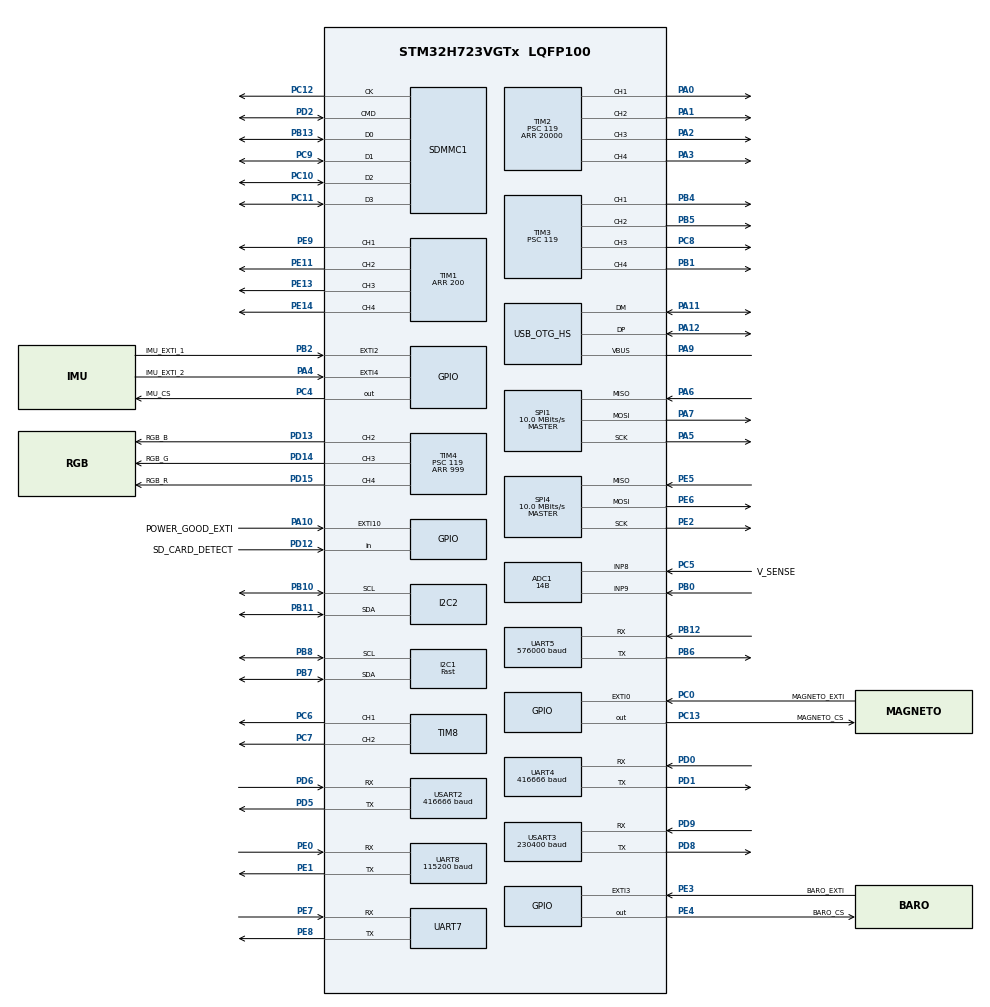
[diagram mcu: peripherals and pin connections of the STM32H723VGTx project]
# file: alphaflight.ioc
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ADC1.Channel-0\#ChannelRegularConversion=ADC_CHANNEL_8
ADC1.Channel-1\#ChannelRegularConversion=ADC_CHANNEL_9
ADC1.ClockPrescaler=ADC_CLOCK_ASYNC_DIV8
ADC1.ConversionDataManagement=ADC_CONVERSIONDATA_DMA_ONESHOT
ADC1.NbrOfConversion=2
ADC1.NbrOfConversionFlag=1
ADC1.OffsetNumber-0\#ChannelRegularConversion=ADC_OFFSET_NONE
ADC1.OffsetNumber-1\#ChannelRegularConversion=ADC_OFFSET_NONE
ADC1.OffsetSignedSaturation-0\#ChannelRegularConversion=DISABLE
ADC1.OversamplingMode=ENABLE
ADC1.Rank-0\#ChannelRegularConversion=1
ADC1.Rank-1\#ChannelRegularConversion=2
ADC1.Ratio=32
ADC1.Resolution=ADC_RESOLUTION_14B
ADC1.RightBitShift=ADC_RIGHTBITSHIFT_5
ADC1.SamplingTime-0\#ChannelRegularConversion=ADC_SAMPLETIME_64CYCLES_5
ADC1.SamplingTime-1\#ChannelRegularConversion=ADC_SAMPLETIME_64CYCLES_5
ADC1.master=1
CORTEX_M7.AccessPermission_Spec=MPU_REGION_FULL_ACCESS
CORTEX_M7.BaseAddress_Spec=0x24000000
CORTEX_M7.CPU_DCache=Enabled
CORTEX_M7.CPU_ICache=Enabled
CORTEX_M7.Enable_S-Cortex_Memory_Protection_Unit_Region1_Settings_S=__NULL
CORTEX_M7.Enable_Spec=MPU_REGION_ENABLE
CORTEX_M7.IsShareable_Spec=MPU_ACCESS_NOT_SHAREABLE
CORTEX_M7.MPU_Control=MPU_HFNMI_PRIVDEF
CORTEX_M7.Size_Spec=MPU_REGION_SIZE_32KB
CORTEX_M7.SubRegionDisable_Spec=0x00
CORTEX_M7.TypeExtField_Spec=MPU_TEX_LEVEL1
CORTEX_M7.default_mode_Activation=1
CRC.InputDataFormat=CRC_INPUTDATA_FORMAT_WORDS
CRC.InputDataInversionMode=CRC_INPUTDATA_INVERSION_BYTE
CRC.OutputDataInversionMode=CRC_OUTPUTDATA_INVERSION_ENABLE
Dma.ADC1.9.Direction=DMA_PERIPH_TO_MEMORY
Dma.ADC1.9.EventEnable=DISABLE
Dma.ADC1.9.FIFOMode=DMA_FIFOMODE_DISABLE
Dma.ADC1.9.Instance=DMA1_Stream4
Dma.ADC1.9.MemDataAlignment=DMA_MDATAALIGN_WORD
Dma.ADC1.9.MemInc=DMA_MINC_ENABLE
Dma.ADC1.9.Mode=DMA_NORMAL
Dma.ADC1.9.PeriphDataAlignment=DMA_PDATAALIGN_WORD
Dma.ADC1.9.PeriphInc=DMA_PINC_DISABLE
Dma.ADC1.9.Polarity=HAL_DMAMUX_REQ_GEN_RISING
Dma.ADC1.9.Priority=DMA_PRIORITY_LOW
Dma.ADC1.9.RequestNumber=1
Dma.ADC1.9.SignalID=NONE
Dma.ADC1.9.SyncEnable=DISABLE
Dma.ADC1.9.SyncPolarity=HAL_DMAMUX_SYNC_NO_EVENT
Dma.ADC1.9.SyncRequestNumber=1
Dma.ADC1.9.SyncSignalID=NONE
Dma.Request0=TIM8_UP
Dma.Request1=SPI1_RX
Dma.Request2=SPI1_TX
Dma.Request3=TIM1_UP
Dma.Request4=USART2_RX
Dma.Request5=USART3_RX
Dma.Request6=UART8_RX
Dma.Request7=UART8_TX
Dma.Request8=USART2_TX
Dma.Request9=ADC1
Dma.SPI1_RX.1.Direction=DMA_PERIPH_TO_MEMORY
Dma.SPI1_RX.1.EventEnable=DISABLE
Dma.SPI1_RX.1.FIFOMode=DMA_FIFOMODE_DISABLE
Dma.SPI1_RX.1.Instance=DMA2_Stream0
Dma.SPI1_RX.1.MemDataAlignment=DMA_MDATAALIGN_BYTE
Dma.SPI1_RX.1.MemInc=DMA_MINC_ENABLE
Dma.SPI1_RX.1.Mode=DMA_NORMAL
Dma.SPI1_RX.1.PeriphDataAlignment=DMA_PDATAALIGN_BYTE
Dma.SPI1_RX.1.PeriphInc=DMA_PINC_DISABLE
Dma.SPI1_RX.1.Polarity=HAL_DMAMUX_REQ_GEN_RISING
Dma.SPI1_RX.1.Priority=DMA_PRIORITY_VERY_HIGH
Dma.SPI1_RX.1.RequestNumber=1
Dma.SPI1_RX.1.SignalID=NONE
Dma.SPI1_RX.1.SyncEnable=DISABLE
Dma.SPI1_RX.1.SyncPolarity=HAL_DMAMUX_SYNC_NO_EVENT
Dma.SPI1_RX.1.SyncRequestNumber=1
Dma.SPI1_RX.1.SyncSignalID=NONE
Dma.SPI1_TX.2.Direction=DMA_MEMORY_TO_PERIPH
Dma.SPI1_TX.2.EventEnable=DISABLE
Dma.SPI1_TX.2.FIFOMode=DMA_FIFOMODE_DISABLE
Dma.SPI1_TX.2.Instance=DMA2_Stream1
Dma.SPI1_TX.2.MemDataAlignment=DMA_MDATAALIGN_BYTE
Dma.SPI1_TX.2.MemInc=DMA_MINC_ENABLE
Dma.SPI1_TX.2.Mode=DMA_NORMAL
Dma.SPI1_TX.2.PeriphDataAlignment=DMA_PDATAALIGN_BYTE
Dma.SPI1_TX.2.PeriphInc=DMA_PINC_DISABLE
Dma.SPI1_TX.2.Polarity=HAL_DMAMUX_REQ_GEN_RISING
Dma.SPI1_TX.2.Priority=DMA_PRIORITY_VERY_HIGH
Dma.SPI1_TX.2.RequestNumber=1
Dma.SPI1_TX.2.SignalID=NONE
Dma.SPI1_TX.2.SyncEnable=DISABLE
Dma.SPI1_TX.2.SyncPolarity=HAL_DMAMUX_SYNC_NO_EVENT
Dma.SPI1_TX.2.SyncRequestNumber=1
Dma.SPI1_TX.2.SyncSignalID=NONE
Dma.TIM1_UP.3.Direction=DMA_MEMORY_TO_PERIPH
Dma.TIM1_UP.3.EventEnable=DISABLE
Dma.TIM1_UP.3.FIFOMode=DMA_FIFOMODE_DISABLE
Dma.TIM1_UP.3.Instance=DMA1_Stream0
Dma.TIM1_UP.3.MemDataAlignment=DMA_MDATAALIGN_HALFWORD
Dma.TIM1_UP.3.MemInc=DMA_MINC_ENABLE
Dma.TIM1_UP.3.Mode=DMA_NORMAL
Dma.TIM1_UP.3.PeriphDataAlignment=DMA_PDATAALIGN_HALFWORD
Dma.TIM1_UP.3.PeriphInc=DMA_PINC_DISABLE
Dma.TIM1_UP.3.Polarity=HAL_DMAMUX_REQ_GEN_RISING
Dma.TIM1_UP.3.Priority=DMA_PRIORITY_VERY_HIGH
Dma.TIM1_UP.3.RequestNumber=1
Dma.TIM1_UP.3.SignalID=NONE
Dma.TIM1_UP.3.SyncEnable=DISABLE
Dma.TIM1_UP.3.SyncPolarity=HAL_DMAMUX_SYNC_NO_EVENT
Dma.TIM1_UP.3.SyncRequestNumber=1
Dma.TIM1_UP.3.SyncSignalID=NONE
Dma.TIM8_UP.0.Direction=DMA_PERIPH_TO_MEMORY
Dma.TIM8_UP.0.EventEnable=DISABLE
Dma.TIM8_UP.0.FIFOMode=DMA_FIFOMODE_DISABLE
Dma.TIM8_UP.0.Instance=DMA1_Stream1
Dma.TIM8_UP.0.MemDataAlignment=DMA_MDATAALIGN_HALFWORD
Dma.TIM8_UP.0.MemInc=DMA_MINC_ENABLE
Dma.TIM8_UP.0.Mode=DMA_NORMAL
Dma.TIM8_UP.0.PeriphDataAlignment=DMA_PDATAALIGN_HALFWORD
Dma.TIM8_UP.0.PeriphInc=DMA_PINC_DISABLE
Dma.TIM8_UP.0.Polarity=HAL_DMAMUX_REQ_GEN_RISING
Dma.TIM8_UP.0.Priority=DMA_PRIORITY_HIGH
Dma.TIM8_UP.0.RequestNumber=1
Dma.TIM8_UP.0.SignalID=NONE
Dma.TIM8_UP.0.SyncEnable=DISABLE
Dma.TIM8_UP.0.SyncPolarity=HAL_DMAMUX_SYNC_NO_EVENT
Dma.TIM8_UP.0.SyncRequestNumber=1
Dma.TIM8_UP.0.SyncSignalID=NONE
Dma.UART8_RX.6.Direction=DMA_PERIPH_TO_MEMORY
Dma.UART8_RX.6.EventEnable=DISABLE
Dma.UART8_RX.6.FIFOMode=DMA_FIFOMODE_DISABLE
Dma.UART8_RX.6.Instance=DMA1_Stream5
Dma.UART8_RX.6.MemDataAlignment=DMA_MDATAALIGN_BYTE
Dma.UART8_RX.6.MemInc=DMA_MINC_ENABLE
Dma.UART8_RX.6.Mode=DMA_CIRCULAR
Dma.UART8_RX.6.PeriphDataAlignment=DMA_PDATAALIGN_BYTE
Dma.UART8_RX.6.PeriphInc=DMA_PINC_DISABLE
Dma.UART8_RX.6.Polarity=HAL_DMAMUX_REQ_GEN_RISING
Dma.UART8_RX.6.Priority=DMA_PRIORITY_LOW
Dma.UART8_RX.6.RequestNumber=1
Dma.UART8_RX.6.SignalID=NONE
Dma.UART8_RX.6.SyncEnable=DISABLE
Dma.UART8_RX.6.SyncPolarity=HAL_DMAMUX_SYNC_NO_EVENT
Dma.UART8_RX.6.SyncRequestNumber=1
Dma.UART8_RX.6.SyncSignalID=NONE
Dma.UART8_TX.7.Direction=DMA_MEMORY_TO_PERIPH
Dma.UART8_TX.7.EventEnable=DISABLE
Dma.UART8_TX.7.FIFOMode=DMA_FIFOMODE_DISABLE
Dma.UART8_TX.7.Instance=DMA1_Stream6
Dma.UART8_TX.7.MemDataAlignment=DMA_MDATAALIGN_BYTE
Dma.UART8_TX.7.MemInc=DMA_MINC_ENABLE
Dma.UART8_TX.7.Mode=DMA_NORMAL
Dma.UART8_TX.7.PeriphDataAlignment=DMA_PDATAALIGN_BYTE
Dma.UART8_TX.7.PeriphInc=DMA_PINC_DISABLE
Dma.UART8_TX.7.Polarity=HAL_DMAMUX_REQ_GEN_RISING
Dma.UART8_TX.7.Priority=DMA_PRIORITY_LOW
Dma.UART8_TX.7.RequestNumber=1
Dma.UART8_TX.7.SignalID=NONE
Dma.UART8_TX.7.SyncEnable=DISABLE
Dma.UART8_TX.7.SyncPolarity=HAL_DMAMUX_SYNC_NO_EVENT
Dma.UART8_TX.7.SyncRequestNumber=1
Dma.UART8_TX.7.SyncSignalID=NONE
Dma.USART2_RX.4.Direction=DMA_PERIPH_TO_MEMORY
Dma.USART2_RX.4.EventEnable=DISABLE
Dma.USART2_RX.4.FIFOMode=DMA_FIFOMODE_DISABLE
Dma.USART2_RX.4.Instance=DMA1_Stream2
Dma.USART2_RX.4.MemDataAlignment=DMA_MDATAALIGN_BYTE
Dma.USART2_RX.4.MemInc=DMA_MINC_ENABLE
Dma.USART2_RX.4.Mode=DMA_CIRCULAR
Dma.USART2_RX.4.PeriphDataAlignment=DMA_PDATAALIGN_BYTE
Dma.USART2_RX.4.PeriphInc=DMA_PINC_DISABLE
Dma.USART2_RX.4.Polarity=HAL_DMAMUX_REQ_GEN_RISING
Dma.USART2_RX.4.Priority=DMA_PRIORITY_HIGH
Dma.USART2_RX.4.RequestNumber=1
Dma.USART2_RX.4.SignalID=NONE
Dma.USART2_RX.4.SyncEnable=DISABLE
Dma.USART2_RX.4.SyncPolarity=HAL_DMAMUX_SYNC_NO_EVENT
Dma.USART2_RX.4.SyncRequestNumber=1
Dma.USART2_RX.4.SyncSignalID=NONE
Dma.USART2_TX.8.Direction=DMA_MEMORY_TO_PERIPH
Dma.USART2_TX.8.EventEnable=DISABLE
Dma.USART2_TX.8.FIFOMode=DMA_FIFOMODE_DISABLE
Dma.USART2_TX.8.Instance=DMA1_Stream7
Dma.USART2_TX.8.MemDataAlignment=DMA_MDATAALIGN_BYTE
Dma.USART2_TX.8.MemInc=DMA_MINC_ENABLE
Dma.USART2_TX.8.Mode=DMA_NORMAL
Dma.USART2_TX.8.PeriphDataAlignment=DMA_PDATAALIGN_BYTE
Dma.USART2_TX.8.PeriphInc=DMA_PINC_DISABLE
Dma.USART2_TX.8.Polarity=HAL_DMAMUX_REQ_GEN_RISING
Dma.USART2_TX.8.Priority=DMA_PRIORITY_LOW
Dma.USART2_TX.8.RequestNumber=1
Dma.USART2_TX.8.SignalID=NONE
Dma.USART2_TX.8.SyncEnable=DISABLE
Dma.USART2_TX.8.SyncPolarity=HAL_DMAMUX_SYNC_NO_EVENT
Dma.USART2_TX.8.SyncRequestNumber=1
Dma.USART2_TX.8.SyncSignalID=NONE
Dma.USART3_RX.5.Direction=DMA_PERIPH_TO_MEMORY
Dma.USART3_RX.5.EventEnable=DISABLE
Dma.USART3_RX.5.FIFOMode=DMA_FIFOMODE_DISABLE
Dma.USART3_RX.5.Instance=DMA1_Stream3
Dma.USART3_RX.5.MemDataAlignment=DMA_MDATAALIGN_BYTE
Dma.USART3_RX.5.MemInc=DMA_MINC_ENABLE
Dma.USART3_RX.5.Mode=DMA_CIRCULAR
Dma.USART3_RX.5.PeriphDataAlignment=DMA_PDATAALIGN_BYTE
Dma.USART3_RX.5.PeriphInc=DMA_PINC_DISABLE
Dma.USART3_RX.5.Polarity=HAL_DMAMUX_REQ_GEN_RISING
Dma.USART3_RX.5.Priority=DMA_PRIORITY_MEDIUM
Dma.USART3_RX.5.RequestNumber=1
Dma.USART3_RX.5.SignalID=NONE
Dma.USART3_RX.5.SyncEnable=DISABLE
Dma.USART3_RX.5.SyncPolarity=HAL_DMAMUX_SYNC_NO_EVENT
Dma.USART3_RX.5.SyncRequestNumber=1
Dma.USART3_RX.5.SyncSignalID=NONE
I2C1.I2C_Speed_Mode=I2C_Fast
I2C1.Timing=0x00501E6C
I2C2.Timing=0x107075B0
Mcu.Family=STM32H7
Mcu.Name=STM32H723VGTx
Mcu.Package=LQFP100
NVIC.DMA1_Stream0_IRQn=true\:0\:0\:false\:false\:true\:false\:true\:true
NVIC.DMA1_Stream1_IRQn=true\:0\:0\:false\:false\:true\:false\:true\:true
NVIC.DMA1_Stream2_IRQn=true\:0\:0\:false\:false\:true\:false\:true\:true
NVIC.DMA1_Stream3_IRQn=true\:0\:0\:false\:false\:true\:false\:true\:true
NVIC.DMA1_Stream4_IRQn=true\:0\:0\:false\:false\:true\:false\:true\:true
NVIC.DMA1_Stream5_IRQn=true\:0\:0\:false\:false\:true\:false\:true\:true
NVIC.DMA1_Stream6_IRQn=true\:0\:0\:false\:false\:true\:false\:true\:true
NVIC.DMA1_Stream7_IRQn=true\:0\:0\:false\:false\:true\:false\:true\:true
NVIC.DMA2_Stream0_IRQn=true\:0\:0\:false\:false\:true\:false\:true\:true
NVIC.DMA2_Stream1_IRQn=true\:0\:0\:false\:false\:true\:false\:true\:true
NVIC.EXTI0_IRQn=true\:13\:0\:true\:false\:true\:true\:true\:true
NVIC.EXTI2_IRQn=true\:5\:0\:true\:false\:true\:true\:true\:true
NVIC.EXTI3_IRQn=true\:14\:0\:true\:false\:true\:true\:true\:true
NVIC.EXTI4_IRQn=true\:6\:0\:true\:false\:true\:true\:true\:true
NVIC.OTG_HS_IRQn=true\:0\:0\:false\:false\:true\:false\:true\:true
NVIC.PriorityGroup=NVIC_PRIORITYGROUP_4
NVIC.SDMMC1_IRQn=true\:0\:0\:false\:false\:true\:true\:true\:true
NVIC.SPI1_IRQn=true\:0\:0\:false\:false\:true\:false\:true\:true
NVIC.UART4_IRQn=true\:0\:0\:false\:false\:true\:true\:true\:true
NVIC.UART5_IRQn=true\:0\:0\:false\:false\:true\:true\:true\:true
NVIC.UART8_IRQn=true\:0\:0\:false\:false\:true\:true\:true\:true
NVIC.USART2_IRQn=true\:0\:0\:false\:false\:true\:true\:true\:true
NVIC.USART3_IRQn=true\:0\:0\:false\:false\:true\:true\:true\:true
PA0.GPIO_Speed=GPIO_SPEED_FREQ_HIGH
PA0.Signal=S_TIM2_CH1_ETR
PA1.GPIO_Speed=GPIO_SPEED_FREQ_HIGH
PA1.Signal=S_TIM2_CH2
PA10.GPIO_Label=POWER_GOOD_EXTI
PA10.Signal=GPXTI10
PA11.Mode=Device_Only_FS
PA11.Signal=USB_OTG_HS_DM
PA12.Mode=Device_Only_FS
PA12.Signal=USB_OTG_HS_DP
PA13(JTMS/SWDIO).Mode=Trace_Asynchronous_SW
PA13(JTMS/SWDIO).Signal=DEBUG_JTMS-SWDIO
PA14(JTCK/SWCLK).Mode=Trace_Asynchronous_SW
PA14(JTCK/SWCLK).Signal=DEBUG_JTCK-SWCLK
PA2.GPIO_Speed=GPIO_SPEED_FREQ_HIGH
PA2.Signal=S_TIM2_CH3
PA3.GPIO_Speed=GPIO_SPEED_FREQ_HIGH
PA3.Signal=S_TIM2_CH4
PA4.GPIO_Label=IMU_EXTI_2
PA4.Signal=GPXTI4
PA5.Mode=Full_Duplex_Master
PA5.Signal=SPI1_SCK
PA6.Mode=Full_Duplex_Master
PA6.Signal=SPI1_MISO
PA7.Mode=Full_Duplex_Master
PA7.Signal=SPI1_MOSI
PA9.Mode=Activate_VBUS_FS
PA9.Signal=USB_OTG_HS_VBUS
PB0.Signal=ADCx_INP9
PB1.GPIO_Speed=GPIO_SPEED_FREQ_HIGH
PB1.Signal=S_TIM3_CH4
PB10.Mode=I2C
PB10.Signal=I2C2_SCL
PB11.Mode=I2C
PB11.Signal=I2C2_SDA
PB12.Mode=Asynchronous
PB12.Signal=UART5_RX
PB13.Mode=SD_4_bits_Wide_bus
PB13.Signal=SDMMC1_D0
PB2.GPIO_Label=IMU_EXTI_1
PB2.GPIO_ModeDefaultEXTI=GPIO_MODE_IT_RISING
PB2.GPIO_PuPd=GPIO_NOPULL
PB2.Signal=GPXTI2
PB3(JTDO/TRACESWO).Mode=Trace_Asynchronous_SW
PB3(JTDO/TRACESWO).Signal=DEBUG_JTDO-SWO
PB4(NJTRST).GPIO_Speed=GPIO_SPEED_FREQ_HIGH
PB4(NJTRST).Signal=S_TIM3_CH1
PB5.GPIO_Speed=GPIO_SPEED_FREQ_HIGH
PB5.Signal=S_TIM3_CH2
PB6.Mode=Asynchronous
PB6.Signal=UART5_TX
PB7.Mode=I2C
PB7.Signal=I2C1_SDA
PB8.Mode=I2C
PB8.Signal=I2C1_SCL
PC0.GPIO_Label=MAGNETO_EXTI
PC0.Signal=GPXTI0
PC10.Mode=SD_4_bits_Wide_bus
PC10.Signal=SDMMC1_D2
PC11.Mode=SD_4_bits_Wide_bus
PC11.Signal=SDMMC1_D3
PC12.Mode=SD_4_bits_Wide_bus
PC12.Signal=SDMMC1_CK
PC13.GPIO_Label=MAGNETO_CS
PC13.Signal=GPIO_Output
PC4.GPIO_Label=IMU_CS
PC4.Signal=GPIO_Output
PC5.GPIO_Label=V_SENSE
PC5.Signal=ADCx_INP8
PC6.Signal=S_TIM8_CH1
PC7.Signal=S_TIM8_CH2
PC8.GPIO_Speed=GPIO_SPEED_FREQ_HIGH
PC8.Signal=S_TIM3_CH3
PC9.Mode=SD_4_bits_Wide_bus
PC9.Signal=SDMMC1_D1
PD0.Mode=Asynchronous
PD0.Signal=UART4_RX
PD1.Mode=Asynchronous
PD1.Signal=UART4_TX
PD12.GPIO_Label=SD_CARD_DETECT
PD12.Signal=GPIO_Input
PD13.GPIO_Label=RGB_B
PD13.Signal=S_TIM4_CH2
PD14.GPIO_Label=RGB_G
PD14.Signal=S_TIM4_CH3
PD15.GPIO_Label=RGB_R
PD15.Signal=S_TIM4_CH4
PD2.Mode=SD_4_bits_Wide_bus
PD2.Signal=SDMMC1_CMD
PD5.Mode=Asynchronous
PD5.Signal=USART2_TX
PD6.Mode=Asynchronous
PD6.Signal=USART2_RX
PD8.Mode=Asynchronous
PD8.Signal=USART3_TX
PD9.Mode=Asynchronous
PD9.Signal=USART3_RX
PE0.Mode=Asynchronous
PE0.Signal=UART8_RX
PE1.Mode=Asynchronous
PE1.Signal=UART8_TX
PE11.GPIO_Speed=GPIO_SPEED_FREQ_VERY_HIGH
PE11.Signal=S_TIM1_CH2
PE13.GPIO_Speed=GPIO_SPEED_FREQ_VERY_HIGH
PE13.Signal=S_TIM1_CH3
PE14.GPIO_Speed=GPIO_SPEED_FREQ_VERY_HIGH
PE14.Signal=S_TIM1_CH4
PE2.Mode=Full_Duplex_Master
PE2.Signal=SPI4_SCK
PE3.GPIO_Label=BARO_EXTI
PE3.Signal=GPXTI3
PE4.GPIO_Label=BARO_CS
PE4.Signal=GPIO_Output
PE5.Mode=Full_Duplex_Master
PE5.Signal=SPI4_MISO
PE6.Mode=Full_Duplex_Master
PE6.Signal=SPI4_MOSI
PE7.Mode=Asynchronous
PE7.Signal=UART7_RX
PE8.Mode=Asynchronous
PE8.Signal=UART7_TX
PE9.GPIO_Speed=GPIO_SPEED_FREQ_VERY_HIGH
PE9.Signal=S_TIM1_CH1
PH0-OSC_IN.Mode=HSE-External-Clock-Source
PH0-OSC_IN.Signal=RCC_OSC_IN
ProjectManager.HeapSize=0x200
ProjectManager.StackSize=0x400
ProjectManager.TargetToolchain=Makefile
RCC.ADCCLockSelection=RCC_ADCCLKSOURCE_PLL3
RCC.ADCFreq_Value=60000000
RCC.APB1Freq_Value=120000000
RCC.APB2Freq_Value=120000000
RCC.APB3Freq_Value=120000000
RCC.APB4Freq_Value=120000000
RCC.CKPERSourceSelection=RCC_CLKPSOURCE_HSE
RCC.CortexFreq_Value=480000000
RCC.DIVM1=8
RCC.DIVM2=8
RCC.DIVM3=8
RCC.DIVN1=120
RCC.DIVN2=120
RCC.DIVN3=120
RCC.DIVP1=1
RCC.DIVP2=24
RCC.DIVP3=1
RCC.DIVQ1=10
RCC.DIVQ2=24
RCC.DIVQ3=8
RCC.DIVR1=10
RCC.DIVR2=4
RCC.DIVR3=8
RCC.HCLKFreq_Value=120000000
RCC.HPRE=RCC_HCLK_DIV4
RCC.HSE_VALUE=32000000
RCC.I2C123CLockSelection=RCC_I2C1235CLKSOURCE_PLL3
RCC.LSE_VALUE=32.768
RCC.PLL1_VCI_Range-AdvancedSettings=RCC_PLL1VCIRANGE_0
RCC.PLL1_VCO_SEL-AdvancedSettings=RCC_PLL1VCOMEDIUM
RCC.PLL2FRACN=0
RCC.PLL2_VCI_Range-AdvancedSettings=RCC_PLL2VCIRANGE_0
RCC.PLL2_VCO_SEL-AdvancedSettings=RCC_PLL2VCOMEDIUM
RCC.PLL3FRACN=0
RCC.PLL3_VCI_Range-AdvancedSettings=RCC_PLL3VCIRANGE_2
RCC.PLL3_VCO_SEL-AdvancedSettings=RCC_PLL3VCOWIDE
RCC.PLLFRACN=0
RCC.PLLSourceVirtual=RCC_PLLSOURCE_HSE
RCC.SDMMC1CLockSelection=RCC_SDMMCCLKSOURCE_PLL2
RCC.SPI123CLockSelection=RCC_SPI123CLKSOURCE_PLL2
RCC.SYSCLKFreq_VALUE=480000000
RCC.SYSCLKSource=RCC_SYSCLKSOURCE_PLLCLK
RCC.Spi45ClockSelection=RCC_SPI45CLKSOURCE_PLL2
RCC.USART234578CLockSelection=RCC_USART234578CLKSOURCE_PLL3
RCC.USBFreq_Value=48000000
SDMMC1.ClockDiv=3
SDMMC1.HardwareFlowControl=SDMMC_HARDWARE_FLOW_CONTROL_ENABLE
SH.ADCx_INP8.0=ADC1_INP8,IN8-Single-Ended
SH.ADCx_INP9.0=ADC1_INP9,IN9-Single-Ended
SH.ADCx_INP9.1=ADC2_INP9
SH.S_TIM1_CH1.0=TIM1_CH1,PWM Generation1 CH1
SH.S_TIM1_CH2.0=TIM1_CH2,PWM Generation2 CH2
SH.S_TIM1_CH3.0=TIM1_CH3,PWM Generation3 CH3
SH.S_TIM1_CH4.0=TIM1_CH4,PWM Generation4 CH4
SH.S_TIM2_CH1_ETR.0=TIM2_CH1,PWM Generation1 CH1
SH.S_TIM2_CH2.0=TIM2_CH2,PWM Generation2 CH2
SH.S_TIM2_CH3.0=TIM2_CH3,PWM Generation3 CH3
SH.S_TIM2_CH4.0=TIM2_CH4,PWM Generation4 CH4
SH.S_TIM3_CH1.0=TIM3_CH1,PWM Generation1 CH1
SH.S_TIM3_CH2.0=TIM3_CH2,PWM Generation2 CH2
SH.S_TIM3_CH3.0=TIM3_CH3,PWM Generation3 CH3
SH.S_TIM3_CH4.0=TIM3_CH4,PWM Generation4 CH4
SH.S_TIM4_CH2.0=TIM4_CH2,PWM Generation2 CH2
SH.S_TIM4_CH3.0=TIM4_CH3,PWM Generation3 CH3
SH.S_TIM4_CH4.0=TIM4_CH4,PWM Generation4 CH4
SH.S_TIM8_CH1.0=TIM8_CH1,Output Compare1 CH1
SH.S_TIM8_CH2.0=TIM8_CH2,Output Compare2 CH2
SPI1.BaudRatePrescaler=SPI_BAUDRATEPRESCALER_2
SPI1.CalculateBaudRate=10.0 MBits/s
SPI1.DataSize=SPI_DATASIZE_8BIT
SPI1.Direction=SPI_DIRECTION_2LINES
SPI1.Mode=SPI_MODE_MASTER
SPI1.VirtualType=VM_MASTER
SPI4.BaudRatePrescaler=SPI_BAUDRATEPRESCALER_2
SPI4.CalculateBaudRate=10.0 MBits/s
SPI4.DataSize=SPI_DATASIZE_8BIT
SPI4.Direction=SPI_DIRECTION_2LINES
SPI4.Mode=SPI_MODE_MASTER
SPI4.VirtualType=VM_MASTER
TIM1.AutoReloadPreload=TIM_AUTORELOAD_PRELOAD_ENABLE
TIM1.Channel-PWM\ Generation1\ CH1=TIM_CHANNEL_1
TIM1.Channel-PWM\ Generation2\ CH2=TIM_CHANNEL_2
TIM1.Channel-PWM\ Generation3\ CH3=TIM_CHANNEL_3
TIM1.Channel-PWM\ Generation4\ CH4=TIM_CHANNEL_4
TIM1.OCFastMode_PWM-PWM\ Generation4\ CH4=TIM_OCFAST_DISABLE
TIM1.Period=200
TIM2.AutoReloadPreload=TIM_AUTORELOAD_PRELOAD_ENABLE
TIM2.Channel-PWM\ Generation1\ CH1=TIM_CHANNEL_1
TIM2.Channel-PWM\ Generation2\ CH2=TIM_CHANNEL_2
TIM2.Channel-PWM\ Generation3\ CH3=TIM_CHANNEL_3
TIM2.Channel-PWM\ Generation4\ CH4=TIM_CHANNEL_4
TIM2.Period=20000
TIM2.Prescaler=119
TIM23.ClockDivision=TIM_CLOCKDIVISION_DIV1
TIM23.Period=4294967295
TIM23.Prescaler=59999
TIM24.Prescaler=119
TIM3.Channel-PWM\ Generation1\ CH1=TIM_CHANNEL_1
TIM3.Channel-PWM\ Generation2\ CH2=TIM_CHANNEL_2
TIM3.Channel-PWM\ Generation3\ CH3=TIM_CHANNEL_3
TIM3.Channel-PWM\ Generation4\ CH4=TIM_CHANNEL_4
TIM3.Prescaler=119
TIM4.AutoReloadPreload=TIM_AUTORELOAD_PRELOAD_ENABLE
TIM4.Channel-PWM\ Generation2\ CH2=TIM_CHANNEL_2
TIM4.Channel-PWM\ Generation3\ CH3=TIM_CHANNEL_3
TIM4.Channel-PWM\ Generation4\ CH4=TIM_CHANNEL_4
TIM4.ClockDivision=TIM_CLOCKDIVISION_DIV1
TIM4.Period=999
TIM4.Prescaler=119
TIM8.Channel-Output\ Compare1\ CH1=TIM_CHANNEL_1
TIM8.Channel-Output\ Compare2\ CH2=TIM_CHANNEL_2
UART4.BaudRate=416666
UART5.BaudRate=576000
UART8.BaudRate=115200
UART8.StopBits=UART_STOPBITS_1
USART2.BaudRate=416666
USART2.VirtualMode-Asynchronous=VM_ASYNC
USART3.BaudRate=230400
USART3.VirtualMode-Asynchronous=VM_ASYNC
USB_DEVICE.CLASS_NAME_HS=CDC
USB_DEVICE.VirtualMode=Cdc
USB_DEVICE.VirtualModeHS=Cdc_HS
USB_OTG_HS.VirtualMode-Device_Only_FS=Device_Only_FS
VP_CORDIC_VS_CORDIC.Mode=CORDIC_Activate
VP_CRC_VS_CRC.Mode=CRC_Activate
VP_MEMORYMAP_VS_MEMORYMAP.Mode=CurAppReg
VP_TIM1_VS_ClockSourceINT.Mode=Internal
VP_TIM23_VS_ClockSourceINT.Mode=Internal
VP_TIM24_VS_ClockSourceINT.Mode=Internal
VP_TIM2_VS_ClockSourceINT.Mode=Internal
VP_TIM3_VS_ClockSourceINT.Mode=Internal
VP_TIM4_VS_ClockSourceINT.Mode=Internal
VP_USB_DEVICE_VS_USB_DEVICE_CDC_HS.Mode=CDC_HS
board=custom

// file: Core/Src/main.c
/* USER CODE BEGIN Header */
/**
  ******************************************************************************
  * @file           : main.c
  * @brief          : Main program body
  ******************************************************************************
  * @attention
  *
  * Copyright (c) 2026 STMicroelectronics.
  * All rights reserved.
  *
  * This software is licensed under terms that can be found in the LICENSE file
  * in the root directory of this software component.
  * If no LICENSE file comes with this software, it is provided AS-IS.
  *
  ******************************************************************************
  */
/* USER CODE END Header */
#include "main.h"
#include "usb_device.h"

/* USER CODE BEGIN Includes */
#include "common.h"
#include "sd.h"
#include "gps.h"
#include "lsm6dso.h"
#include "bmp390.h"
#include "timer.h"
#include "scheduler.h"
#include "spi.h"
#include "usbd_cdc.h"
#include "status_led.h"
#include "usb.h"
#include "config.h"
#include "dshot.h"
#include "serial_passthrough.h"
#include "crossfire.h"
#include "logger.h"
#include "flight_control.h"
#include "filesystem.h"
#include "osd.h"
#include "mmc5983ma.h"
#include "power_measurement.h"
/* USER CODE END Includes */

/* USER CODE BEGIN PM */

static inline uint32_t HZ_TO_US(float hz){
    if (hz <= 0.0f) return 0xFFFFFFFF; // avoid div by zero
    float period = 1.0f / hz * 1e6f;
    if (period > 0xFFFFFFFF) return 0xFFFFFFFF; // clamp to max uint32
    return (uint32_t)period;
}

/* USER CODE END PM */

ADC_HandleTypeDef hadc1;
DMA_HandleTypeDef hdma_adc1;

I2C_HandleTypeDef hi2c1;
I2C_HandleTypeDef hi2c2;

SD_HandleTypeDef hsd1;

SPI_HandleTypeDef hspi1;
SPI_HandleTypeDef hspi4;
DMA_HandleTypeDef hdma_spi1_rx;
DMA_HandleTypeDef hdma_spi1_tx;

UART_HandleTypeDef huart4;
UART_HandleTypeDef huart5;
UART_HandleTypeDef huart7;
UART_HandleTypeDef huart8;
UART_HandleTypeDef huart2;
UART_HandleTypeDef huart3;
DMA_HandleTypeDef hdma_uart8_rx;
DMA_HandleTypeDef hdma_uart8_tx;
DMA_HandleTypeDef hdma_usart2_rx;
DMA_HandleTypeDef hdma_usart2_tx;
DMA_HandleTypeDef hdma_usart3_rx;

void SystemClock_Config(void);
void PeriphCommonClock_Config(void);
static void MPU_Config(void);
static void MX_GPIO_Init(void);
static void MX_DMA_Init(void);
static void MX_CORDIC_Init(void);
static void MX_CRC_Init(void);
static void MX_SPI1_Init(void);
static void MX_TIM1_Init(void);
static void MX_TIM2_Init(void);
static void MX_TIM3_Init(void);
static void MX_TIM24_Init(void);
static void MX_I2C1_Init(void);
static void MX_SDMMC1_SD_Init(void);
static void MX_UART4_Init(void);
static void MX_UART5_Init(void);
static void MX_UART7_Init(void);
static void MX_UART8_Init(void);
static void MX_USART2_UART_Init(void);
static void MX_USART3_UART_Init(void);
static void MX_I2C2_Init(void);
static void MX_SPI4_Init(void);
static void MX_TIM8_Init(void);
static void MX_TIM4_Init(void);
static void MX_TIM23_Init(void);
static void MX_ADC1_Init(void);

int main(void)
{

  /* MPU Configuration--------------------------------------------------------*/
  MPU_Config();

  /* Enable the CPU Cache */

  /* Enable I-Cache---------------------------------------------------------*/
  SCB_EnableICache();

  /* Enable D-Cache---------------------------------------------------------*/
  SCB_EnableDCache();

  /* MCU Configuration--------------------------------------------------------*/

  /* Reset of all peripherals, Initializes the Flash interface and the Systick. */
  HAL_Init();

  /* Configure the system clock */
  SystemClock_Config();

  /* Configure the peripherals common clocks */
  PeriphCommonClock_Config();

  /* Initialize all configured peripherals */
  MX_GPIO_Init();
  MX_DMA_Init();
  MX_CORDIC_Init();
  MX_CRC_Init();
  MX_SPI1_Init();
  MX_TIM1_Init();
  MX_TIM2_Init();
  MX_TIM3_Init();
  MX_TIM24_Init();
  MX_I2C1_Init();
  MX_SDMMC1_SD_Init();
  MX_UART4_Init();
  MX_UART5_Init();
  MX_UART7_Init();
  MX_UART8_Init();
  MX_USART2_UART_Init();
  MX_USART3_UART_Init();
  MX_I2C2_Init();
  MX_SPI4_Init();
  MX_TIM8_Init();
  MX_USB_DEVICE_Init();
  MX_TIM4_Init();
  MX_TIM23_Init();
  MX_ADC1_Init();
  /* USER CODE BEGIN 2 */

  STATUS_LED_INIT();

  //PASSTHROUGH_START(&huart8);

  extern uint32_t alphaflight_cpp_test(void);

  uint32_t result = alphaflight_cpp_test();

  if(CONFIG_STORE_TO_SD_DEFAULTS() != CONFIG_OKAY) Error_Handler();

  if(CONFIG_LOAD_FROM_SD() != CONFIG_OKAY) Error_Handler();   // load complete FC config

  //fs_reset_superblock();

  if(TIMER_INIT(TIM23, TIM24) != TIMER_INIT_OKAY) Error_Handler();  // timer init for MICROS32 and MILLIS32

  if(TIMER_START() != TIMER_OKAY) Error_Handler();    // start MICROS32 and MILLIS32 timers

  SPI_INIT(SPI_DEVICE_IMU, &hspi1, GPIOC, LL_GPIO_PIN_4);   // initialize SPI devices
  SPI_INIT(SPI_DEVICE_BARO, &hspi4, GPIOE, LL_GPIO_PIN_4);
  SPI_INIT(SPI_DEVICE_MAGNETO, &hspi4, GPIOC, LL_GPIO_PIN_13);

  int32_t imu_task_index = SCHEDULER_REGISTER_TASK(IMU_READ_DATA, 600, false, 500, 800, 25, "Gyro Read");  // init IMU and register task in case of DRDY mode
  if(IMU_INIT(SPI_DEVICE_IMU, imu_task_index, &hdma_spi1_rx) != IMU_OKAY) Error_Handler();

  FS_LOAD_SUPERBLOCK();

  SERVO_INIT(TIM2, TIM3);

  if(BARO_INIT(SPI_DEVICE_BARO) != BARO_OKAY) Error_Handler();

  if(MAGNETO_INIT(SPI_DEVICE_MAGNETO) != MAGNETO_OKAY) Error_Handler();

  DSHOT_INIT();

  SCHEDULER_REGISTER_TASK(DSHOT_TRANSMIT, HZ_TO_US(1000), false, 0, 0, 20, "DSHOT TX");
  CRSF_SET_PARSER_TASK_PID(SCHEDULER_REGISTER_TASK(CRSF_PARSE_DMA, 100, false, 50, 150, 50, "CRSF Parsing"));
  GPS_SET_PARSER_TASK_PID(SCHEDULER_REGISTER_TASK(GPS_PARSE_DMA, 100, false, 50, 150, 50, "GPS Parsing"));
  SCHEDULER_REGISTER_TASK(FC_DIRECT_LAW, HZ_TO_US(200), false, 0, 0, 10, "FC Dir Law");
  LOG_SET_TASK_PID(SCHEDULER_REGISTER_TASK(LOG_RUN, HZ_TO_US(LOG_GET_FREQUENCY()), false, 0, 0, 10, "SD Logger"));
  SCHEDULER_REGISTER_TASK(BARO_READ_DATA, HZ_TO_US(25), false, HZ_TO_US(30), HZ_TO_US(20), 30, "Baro read");
  SCHEDULER_REGISTER_TASK(CRSF_TELEMETRY, HZ_TO_US(20), false, 0, 0, 10, "CRSF Telemetry");
  SCHEDULER_REGISTER_TASK(POWER_MEASUREMENT_START_DMA_READ, HZ_TO_US(100), false, 100, 100, 100, "ADC DMA start");
  //SCHEDULER_REGISTER_TASK(SCHEDULER_PRINT_TASK_PAGE, HZ_TO_US(10), false, 90000, 110000, 500, "USB Stats");
  //SCHEDULER_REGISTER_TASK(USB_STATUS, HZ_TO_US(60), false, 90000, 110000, 500, "USB Stats");

  GPS_INIT(&huart3);
  CRSF_INIT(&huart2);
  OSD_INIT(&huart8);
  POWER_MEASUREMENT_INIT(&hadc1);
  STATUS_LED_SET_ALL(20);

  /* USER CODE END 2 */

  /* Infinite loop */
  /* USER CODE BEGIN WHILE */
  while (1)
  {
    SCHEDULER_LOOP();

    /*if(latch == 0 && (MILLIS32() - now) > 20000){
      LOG_START();
      now = MILLIS32();
      latch = 1;
      STATUS_LED_SET_ALL(999);
    }

    if(latch == 1 && (MILLIS32() - now) > 20000){
      LOG_END();
      latch = 2;
      STATUS_LED_SET_ALL(20);
    }*/

    /* USER CODE END WHILE */

    /* USER CODE BEGIN 3 */
    /*
    Debug pin on S1:
    volatile static bool debug = false;

    GPIOA->MODER &= ~(uint32_t)0x03;
    GPIOA->MODER |= (uint32_t)0x01;

    if(debug){
        GPIOA->BSRR = 0x01;
    }
    else{
        GPIOA->BSRR = 0x01 << 16;
    }
    debug = !debug;
    */
  }
  /* USER CODE END 3 */
}

void SystemClock_Config(void)
{
  LL_FLASH_SetLatency(LL_FLASH_LATENCY_2);
  while(LL_FLASH_GetLatency()!= LL_FLASH_LATENCY_2)
  {
  }
  LL_PWR_ConfigSupply(LL_PWR_LDO_SUPPLY);
  LL_PWR_SetRegulVoltageScaling(LL_PWR_REGU_VOLTAGE_SCALE2);
  while (LL_PWR_IsActiveFlag_VOS() == 0)
  {
  }
  LL_RCC_HSE_EnableBypass();
  LL_RCC_HSE_Enable();

   /* Wait till HSE is ready */
  while(LL_RCC_HSE_IsReady() != 1)
  {

  }
  LL_RCC_PLL_SetSource(LL_RCC_PLLSOURCE_HSE);
  LL_RCC_PLL1P_Enable();
  LL_RCC_PLL1Q_Enable();
  LL_RCC_PLL1R_Enable();
  LL_RCC_PLL1_SetVCOInputRange(LL_RCC_PLLINPUTRANGE_4_8);
  LL_RCC_PLL1_SetVCOOutputRange(LL_RCC_PLLVCORANGE_WIDE);
  LL_RCC_PLL1_SetM(8);
  LL_RCC_PLL1_SetN(120);
  LL_RCC_PLL1_SetP(1);
  LL_RCC_PLL1_SetQ(10);
  LL_RCC_PLL1_SetR(10);
  LL_RCC_PLL1_Enable();

   /* Wait till PLL is ready */
  while(LL_RCC_PLL1_IsReady() != 1)
  {
  }

   /* Intermediate AHB prescaler 2 when target frequency clock is higher than 80 MHz */
   LL_RCC_SetAHBPrescaler(LL_RCC_AHB_DIV_2);

  LL_RCC_SetSysClkSource(LL_RCC_SYS_CLKSOURCE_PLL1);

   /* Wait till System clock is ready */
  while(LL_RCC_GetSysClkSource() != LL_RCC_SYS_CLKSOURCE_STATUS_PLL1)
  {

  }
  LL_RCC_SetSysPrescaler(LL_RCC_SYSCLK_DIV_1);
  LL_RCC_SetAHBPrescaler(LL_RCC_AHB_DIV_4);
  LL_RCC_SetAPB1Prescaler(LL_RCC_APB1_DIV_1);
  LL_RCC_SetAPB2Prescaler(LL_RCC_APB2_DIV_1);
  LL_RCC_SetAPB3Prescaler(LL_RCC_APB3_DIV_1);
  LL_RCC_SetAPB4Prescaler(LL_RCC_APB4_DIV_1);
  LL_SetSystemCoreClock(480000000);

   /* Update the time base */
  if (HAL_InitTick (TICK_INT_PRIORITY) != HAL_OK)
  {
    Error_Handler();
  }
}

void PeriphCommonClock_Config(void)
{
  LL_RCC_PLL2P_Enable();
  LL_RCC_PLL2Q_Enable();
  LL_RCC_PLL2R_Enable();
  LL_RCC_PLL2_SetVCOInputRange(LL_RCC_PLLINPUTRANGE_4_8);
  LL_RCC_PLL2_SetVCOOutputRange(LL_RCC_PLLVCORANGE_WIDE);
  LL_RCC_PLL2_SetM(8);
  LL_RCC_PLL2_SetN(120);
  LL_RCC_PLL2_SetP(24);
  LL_RCC_PLL2_SetQ(24);
  LL_RCC_PLL2_SetR(4);
  LL_RCC_PLL2_Enable();

   /* Wait till PLL is ready */
  while(LL_RCC_PLL2_IsReady() != 1)
  {
  }

  LL_RCC_PLL3Q_Enable();
  LL_RCC_PLL3R_Enable();
  LL_RCC_PLL3_SetVCOInputRange(LL_RCC_PLLINPUTRANGE_4_8);
  LL_RCC_PLL3_SetVCOOutputRange(LL_RCC_PLLVCORANGE_WIDE);
  LL_RCC_PLL3_SetM(8);
  LL_RCC_PLL3_SetN(120);
  LL_RCC_PLL3_SetP(1);
  LL_RCC_PLL3_SetQ(8);
  LL_RCC_PLL3_SetR(8);
  LL_RCC_PLL3_Enable();

   /* Wait till PLL is ready */
  while(LL_RCC_PLL3_IsReady() != 1)
  {
  }

}

static void MX_ADC1_Init(void)
{

  ADC_MultiModeTypeDef multimode = {0};
  ADC_ChannelConfTypeDef sConfig = {0};

  /** Common config
  */
  hadc1.Instance = ADC1;
  hadc1.Init.ClockPrescaler = ADC_CLOCK_ASYNC_DIV8;
  hadc1.Init.Resolution = ADC_RESOLUTION_14B;
  hadc1.Init.ScanConvMode = ADC_SCAN_ENABLE;
  hadc1.Init.EOCSelection = ADC_EOC_SINGLE_CONV;
  hadc1.Init.LowPowerAutoWait = DISABLE;
  hadc1.Init.ContinuousConvMode = DISABLE;
  hadc1.Init.NbrOfConversion = 2;
  hadc1.Init.DiscontinuousConvMode = DISABLE;
  hadc1.Init.ExternalTrigConv = ADC_SOFTWARE_START;
  hadc1.Init.ExternalTrigConvEdge = ADC_EXTERNALTRIGCONVEDGE_NONE;
  hadc1.Init.ConversionDataManagement = ADC_CONVERSIONDATA_DMA_ONESHOT;
  hadc1.Init.Overrun = ADC_OVR_DATA_PRESERVED;
  hadc1.Init.LeftBitShift = ADC_LEFTBITSHIFT_NONE;
  hadc1.Init.OversamplingMode = ENABLE;
  hadc1.Init.Oversampling.Ratio = 32;
  hadc1.Init.Oversampling.RightBitShift = ADC_RIGHTBITSHIFT_5;
  hadc1.Init.Oversampling.TriggeredMode = ADC_TRIGGEREDMODE_SINGLE_TRIGGER;
  hadc1.Init.Oversampling.OversamplingStopReset = ADC_REGOVERSAMPLING_CONTINUED_MODE;
  if (HAL_ADC_Init(&hadc1) != HAL_OK)
  {
    Error_Handler();
  }

  /** Configure the ADC multi-mode
  */
  multimode.Mode = ADC_MODE_INDEPENDENT;
  if (HAL_ADCEx_MultiModeConfigChannel(&hadc1, &multimode) != HAL_OK)
  {
    Error_Handler();
  }

  /** Configure Regular Channel
  */
  sConfig.Channel = ADC_CHANNEL_8;
  sConfig.Rank = ADC_REGULAR_RANK_1;
  sConfig.SamplingTime = ADC_SAMPLETIME_64CYCLES_5;
  sConfig.SingleDiff = ADC_SINGLE_ENDED;
  sConfig.OffsetNumber = ADC_OFFSET_NONE;
  sConfig.Offset = 0;
  sConfig.OffsetSignedSaturation = DISABLE;
  if (HAL_ADC_ConfigChannel(&hadc1, &sConfig) != HAL_OK)
  {
    Error_Handler();
  }

  /** Configure Regular Channel
  */
  sConfig.Channel = ADC_CHANNEL_9;
  sConfig.Rank = ADC_REGULAR_RANK_2;
  if (HAL_ADC_ConfigChannel(&hadc1, &sConfig) != HAL_OK)
  {
    Error_Handler();
  }

}

static void MX_CORDIC_Init(void)
{

  /* Peripheral clock enable */
  __HAL_RCC_CORDIC_CLK_ENABLE();

  /* nothing else to be configured */

}

static void MX_CRC_Init(void)
{

  /* Peripheral clock enable */
  LL_AHB4_GRP1_EnableClock(LL_AHB4_GRP1_PERIPH_CRC);

  LL_CRC_SetInputDataReverseMode(CRC, LL_CRC_INDATA_REVERSE_BYTE);
  LL_CRC_SetOutputDataReverseMode(CRC, LL_CRC_OUTDATA_REVERSE_BIT);
  LL_CRC_SetPolynomialCoef(CRC, LL_CRC_DEFAULT_CRC32_POLY);
  LL_CRC_SetPolynomialSize(CRC, LL_CRC_POLYLENGTH_32B);
  LL_CRC_SetInitialData(CRC, LL_CRC_DEFAULT_CRC_INITVALUE);

}

static void MX_I2C1_Init(void)
{

  hi2c1.Instance = I2C1;
  hi2c1.Init.Timing = 0x00501E6C;
  hi2c1.Init.OwnAddress1 = 0;
  hi2c1.Init.AddressingMode = I2C_ADDRESSINGMODE_7BIT;
  hi2c1.Init.DualAddressMode = I2C_DUALADDRESS_DISABLE;
  hi2c1.Init.OwnAddress2 = 0;
  hi2c1.Init.OwnAddress2Masks = I2C_OA2_NOMASK;
  hi2c1.Init.GeneralCallMode = I2C_GENERALCALL_DISABLE;
  hi2c1.Init.NoStretchMode = I2C_NOSTRETCH_DISABLE;
  if (HAL_I2C_Init(&hi2c1) != HAL_OK)
  {
    Error_Handler();
  }

  /** Configure Analogue filter
  */
  if (HAL_I2CEx_ConfigAnalogFilter(&hi2c1, I2C_ANALOGFILTER_ENABLE) != HAL_OK)
  {
    Error_Handler();
  }

  /** Configure Digital filter
  */
  if (HAL_I2CEx_ConfigDigitalFilter(&hi2c1, 0) != HAL_OK)
  {
    Error_Handler();
  }

}

static void MX_I2C2_Init(void)
{

  hi2c2.Instance = I2C2;
  hi2c2.Init.Timing = 0x107075B0;
  hi2c2.Init.OwnAddress1 = 0;
  hi2c2.Init.AddressingMode = I2C_ADDRESSINGMODE_7BIT;
  hi2c2.Init.DualAddressMode = I2C_DUALADDRESS_DISABLE;
  hi2c2.Init.OwnAddress2 = 0;
  hi2c2.Init.OwnAddress2Masks = I2C_OA2_NOMASK;
  hi2c2.Init.GeneralCallMode = I2C_GENERALCALL_DISABLE;
  hi2c2.Init.NoStretchMode = I2C_NOSTRETCH_DISABLE;
  if (HAL_I2C_Init(&hi2c2) != HAL_OK)
  {
    Error_Handler();
  }

  /** Configure Analogue filter
  */
  if (HAL_I2CEx_ConfigAnalogFilter(&hi2c2, I2C_ANALOGFILTER_ENABLE) != HAL_OK)
  {
    Error_Handler();
  }

  /** Configure Digital filter
  */
  if (HAL_I2CEx_ConfigDigitalFilter(&hi2c2, 0) != HAL_OK)
  {
    Error_Handler();
  }

}

static void MX_SDMMC1_SD_Init(void)
{

  hsd1.Instance = SDMMC1;
  hsd1.Init.ClockEdge = SDMMC_CLOCK_EDGE_RISING;
  hsd1.Init.ClockPowerSave = SDMMC_CLOCK_POWER_SAVE_DISABLE;
  hsd1.Init.BusWide = SDMMC_BUS_WIDE_4B;
  hsd1.Init.HardwareFlowControl = SDMMC_HARDWARE_FLOW_CONTROL_ENABLE;
  hsd1.Init.ClockDiv = 3;
  if (HAL_SD_Init(&hsd1) != HAL_OK)
  {
    Error_Handler();
  }

}

static void MX_SPI1_Init(void)
{

  /* SPI1 parameter configuration*/
  hspi1.Instance = SPI1;
  hspi1.Init.Mode = SPI_MODE_MASTER;
  hspi1.Init.Direction = SPI_DIRECTION_2LINES;
  hspi1.Init.DataSize = SPI_DATASIZE_8BIT;
  hspi1.Init.CLKPolarity = SPI_POLARITY_LOW;
  hspi1.Init.CLKPhase = SPI_PHASE_1EDGE;
  hspi1.Init.NSS = SPI_NSS_SOFT;
  hspi1.Init.BaudRatePrescaler = SPI_BAUDRATEPRESCALER_2;
  hspi1.Init.FirstBit = SPI_FIRSTBIT_MSB;
  hspi1.Init.TIMode = SPI_TIMODE_DISABLE;
  hspi1.Init.CRCCalculation = SPI_CRCCALCULATION_DISABLE;
  hspi1.Init.CRCPolynomial = 0x0;
  hspi1.Init.NSSPMode = SPI_NSS_PULSE_ENABLE;
  hspi1.Init.NSSPolarity = SPI_NSS_POLARITY_LOW;
  hspi1.Init.FifoThreshold = SPI_FIFO_THRESHOLD_01DATA;
  hspi1.Init.TxCRCInitializationPattern = SPI_CRC_INITIALIZATION_ALL_ZERO_PATTERN;
  hspi1.Init.RxCRCInitializationPattern = SPI_CRC_INITIALIZATION_ALL_ZERO_PATTERN;
  hspi1.Init.MasterSSIdleness = SPI_MASTER_SS_IDLENESS_00CYCLE;
  hspi1.Init.MasterInterDataIdleness = SPI_MASTER_INTERDATA_IDLENESS_00CYCLE;
  hspi1.Init.MasterReceiverAutoSusp = SPI_MASTER_RX_AUTOSUSP_DISABLE;
  hspi1.Init.MasterKeepIOState = SPI_MASTER_KEEP_IO_STATE_DISABLE;
  hspi1.Init.IOSwap = SPI_IO_SWAP_DISABLE;
  if (HAL_SPI_Init(&hspi1) != HAL_OK)
  {
    Error_Handler();
  }

}

static void MX_SPI4_Init(void)
{

  /* SPI4 parameter configuration*/
  hspi4.Instance = SPI4;
  hspi4.Init.Mode = SPI_MODE_MASTER;
  hspi4.Init.Direction = SPI_DIRECTION_2LINES;
  hspi4.Init.DataSize = SPI_DATASIZE_8BIT;
  hspi4.Init.CLKPolarity = SPI_POLARITY_LOW;
  hspi4.Init.CLKPhase = SPI_PHASE_1EDGE;
  hspi4.Init.NSS = SPI_NSS_SOFT;
  hspi4.Init.BaudRatePrescaler = SPI_BAUDRATEPRESCALER_2;
  hspi4.Init.FirstBit = SPI_FIRSTBIT_MSB;
  hspi4.Init.TIMode = SPI_TIMODE_DISABLE;
  hspi4.Init.CRCCalculation = SPI_CRCCALCULATION_DISABLE;
  hspi4.Init.CRCPolynomial = 0x0;
  hspi4.Init.NSSPMode = SPI_NSS_PULSE_ENABLE;
  hspi4.Init.NSSPolarity = SPI_NSS_POLARITY_LOW;
  hspi4.Init.FifoThreshold = SPI_FIFO_THRESHOLD_01DATA;
  hspi4.Init.TxCRCInitializationPattern = SPI_CRC_INITIALIZATION_ALL_ZERO_PATTERN;
  hspi4.Init.RxCRCInitializationPattern = SPI_CRC_INITIALIZATION_ALL_ZERO_PATTERN;
  hspi4.Init.MasterSSIdleness = SPI_MASTER_SS_IDLENESS_00CYCLE;
  hspi4.Init.MasterInterDataIdleness = SPI_MASTER_INTERDATA_IDLENESS_00CYCLE;
  hspi4.Init.MasterReceiverAutoSusp = SPI_MASTER_RX_AUTOSUSP_DISABLE;
  hspi4.Init.MasterKeepIOState = SPI_MASTER_KEEP_IO_STATE_DISABLE;
  hspi4.Init.IOSwap = SPI_IO_SWAP_DISABLE;
  if (HAL_SPI_Init(&hspi4) != HAL_OK)
  {
    Error_Handler();
  }

}

static void MX_TIM1_Init(void)
{

  LL_TIM_InitTypeDef TIM_InitStruct = {0};
  LL_TIM_OC_InitTypeDef TIM_OC_InitStruct = {0};
  LL_TIM_BDTR_InitTypeDef TIM_BDTRInitStruct = {0};

  LL_GPIO_InitTypeDef GPIO_InitStruct = {0};

  /* Peripheral clock enable */
  LL_APB2_GRP1_EnableClock(LL_APB2_GRP1_PERIPH_TIM1);

  /* TIM1 DMA Init */

  /* TIM1_UP Init */
  LL_DMA_SetPeriphRequest(DMA1, LL_DMA_STREAM_0, LL_DMAMUX1_REQ_TIM1_UP);

  LL_DMA_SetDataTransferDirection(DMA1, LL_DMA_STREAM_0, LL_DMA_DIRECTION_MEMORY_TO_PERIPH);

  LL_DMA_SetStreamPriorityLevel(DMA1, LL_DMA_STREAM_0, LL_DMA_PRIORITY_VERYHIGH);

  LL_DMA_SetMode(DMA1, LL_DMA_STREAM_0, LL_DMA_MODE_NORMAL);

  LL_DMA_SetPeriphIncMode(DMA1, LL_DMA_STREAM_0, LL_DMA_PERIPH_NOINCREMENT);

  LL_DMA_SetMemoryIncMode(DMA1, LL_DMA_STREAM_0, LL_DMA_MEMORY_INCREMENT);

  LL_DMA_SetPeriphSize(DMA1, LL_DMA_STREAM_0, LL_DMA_PDATAALIGN_HALFWORD);

  LL_DMA_SetMemorySize(DMA1, LL_DMA_STREAM_0, LL_DMA_MDATAALIGN_HALFWORD);

  LL_DMA_DisableFifoMode(DMA1, LL_DMA_STREAM_0);

  TIM_InitStruct.Prescaler = 0;
  TIM_InitStruct.CounterMode = LL_TIM_COUNTERMODE_UP;
  TIM_InitStruct.Autoreload = 200;
  TIM_InitStruct.ClockDivision = LL_TIM_CLOCKDIVISION_DIV1;
  TIM_InitStruct.RepetitionCounter = 0;
  LL_TIM_Init(TIM1, &TIM_InitStruct);
  LL_TIM_EnableARRPreload(TIM1);
  LL_TIM_SetClockSource(TIM1, LL_TIM_CLOCKSOURCE_INTERNAL);
  LL_TIM_OC_EnablePreload(TIM1, LL_TIM_CHANNEL_CH1);
  TIM_OC_InitStruct.OCMode = LL_TIM_OCMODE_PWM1;
  TIM_OC_InitStruct.OCState = LL_TIM_OCSTATE_DISABLE;
  TIM_OC_InitStruct.OCNState = LL_TIM_OCSTATE_DISABLE;
  TIM_OC_InitStruct.CompareValue = 0;
  TIM_OC_InitStruct.OCPolarity = LL_TIM_OCPOLARITY_HIGH;
  TIM_OC_InitStruct.OCNPolarity = LL_TIM_OCPOLARITY_HIGH;
  TIM_OC_InitStruct.OCIdleState = LL_TIM_OCIDLESTATE_LOW;
  TIM_OC_InitStruct.OCNIdleState = LL_TIM_OCIDLESTATE_LOW;
  LL_TIM_OC_Init(TIM1, LL_TIM_CHANNEL_CH1, &TIM_OC_InitStruct);
  LL_TIM_OC_DisableFast(TIM1, LL_TIM_CHANNEL_CH1);
  LL_TIM_OC_EnablePreload(TIM1, LL_TIM_CHANNEL_CH2);
  LL_TIM_OC_Init(TIM1, LL_TIM_CHANNEL_CH2, &TIM_OC_InitStruct);
  LL_TIM_OC_DisableFast(TIM1, LL_TIM_CHANNEL_CH2);
  LL_TIM_OC_EnablePreload(TIM1, LL_TIM_CHANNEL_CH3);
  LL_TIM_OC_Init(TIM1, LL_TIM_CHANNEL_CH3, &TIM_OC_InitStruct);
  LL_TIM_OC_DisableFast(TIM1, LL_TIM_CHANNEL_CH3);
  LL_TIM_OC_EnablePreload(TIM1, LL_TIM_CHANNEL_CH4);
  LL_TIM_OC_Init(TIM1, LL_TIM_CHANNEL_CH4, &TIM_OC_InitStruct);
  LL_TIM_OC_DisableFast(TIM1, LL_TIM_CHANNEL_CH4);
  LL_TIM_SetTriggerOutput(TIM1, LL_TIM_TRGO_RESET);
  LL_TIM_SetTriggerOutput2(TIM1, LL_TIM_TRGO2_RESET);
  LL_TIM_DisableMasterSlaveMode(TIM1);
  TIM_BDTRInitStruct.OSSRState = LL_TIM_OSSR_DISABLE;
  TIM_BDTRInitStruct.OSSIState = LL_TIM_OSSI_DISABLE;
  TIM_BDTRInitStruct.LockLevel = LL_TIM_LOCKLEVEL_OFF;
  TIM_BDTRInitStruct.DeadTime = 0;
  TIM_BDTRInitStruct.BreakState = LL_TIM_BREAK_DISABLE;
  TIM_BDTRInitStruct.BreakPolarity = LL_TIM_BREAK_POLARITY_HIGH;
  TIM_BDTRInitStruct.BreakFilter = LL_TIM_BREAK_FILTER_FDIV1;
  TIM_BDTRInitStruct.Break2State = LL_TIM_BREAK2_DISABLE;
  TIM_BDTRInitStruct.Break2Polarity = LL_TIM_BREAK2_POLARITY_HIGH;
  TIM_BDTRInitStruct.Break2Filter = LL_TIM_BREAK2_FILTER_FDIV1;
  TIM_BDTRInitStruct.AutomaticOutput = LL_TIM_AUTOMATICOUTPUT_DISABLE;
  LL_TIM_BDTR_Init(TIM1, &TIM_BDTRInitStruct);
  LL_AHB4_GRP1_EnableClock(LL_AHB4_GRP1_PERIPH_GPIOE);
  /**TIM1 GPIO Configuration
  PE9   ------> TIM1_CH1
  PE11   ------> TIM1_CH2
  PE13   ------> TIM1_CH3
  PE14   ------> TIM1_CH4
  */
  GPIO_InitStruct.Pin = LL_GPIO_PIN_9|LL_GPIO_PIN_11|LL_GPIO_PIN_13|LL_GPIO_PIN_14;
  GPIO_InitStruct.Mode = LL_GPIO_MODE_ALTERNATE;
  GPIO_InitStruct.Speed = LL_GPIO_SPEED_FREQ_VERY_HIGH;
  GPIO_InitStruct.OutputType = LL_GPIO_OUTPUT_PUSHPULL;
  GPIO_InitStruct.Pull = LL_GPIO_PULL_NO;
  GPIO_InitStruct.Alternate = LL_GPIO_AF_1;
  LL_GPIO_Init(GPIOE, &GPIO_InitStruct);

}

static void MX_TIM2_Init(void)
{

  LL_TIM_InitTypeDef TIM_InitStruct = {0};
  LL_TIM_OC_InitTypeDef TIM_OC_InitStruct = {0};

  LL_GPIO_InitTypeDef GPIO_InitStruct = {0};

  /* Peripheral clock enable */
  LL_APB1_GRP1_EnableClock(LL_APB1_GRP1_PERIPH_TIM2);

  TIM_InitStruct.Prescaler = 119;
  TIM_InitStruct.CounterMode = LL_TIM_COUNTERMODE_UP;
  TIM_InitStruct.Autoreload = 20000;
  TIM_InitStruct.ClockDivision = LL_TIM_CLOCKDIVISION_DIV1;
  LL_TIM_Init(TIM2, &TIM_InitStruct);
  LL_TIM_EnableARRPreload(TIM2);
  LL_TIM_SetClockSource(TIM2, LL_TIM_CLOCKSOURCE_INTERNAL);
  LL_TIM_OC_EnablePreload(TIM2, LL_TIM_CHANNEL_CH1);
  TIM_OC_InitStruct.OCMode = LL_TIM_OCMODE_PWM1;
  TIM_OC_InitStruct.OCState = LL_TIM_OCSTATE_DISABLE;
  TIM_OC_InitStruct.OCNState = LL_TIM_OCSTATE_DISABLE;
  TIM_OC_InitStruct.CompareValue = 0;
  TIM_OC_InitStruct.OCPolarity = LL_TIM_OCPOLARITY_HIGH;
  LL_TIM_OC_Init(TIM2, LL_TIM_CHANNEL_CH1, &TIM_OC_InitStruct);
  LL_TIM_OC_DisableFast(TIM2, LL_TIM_CHANNEL_CH1);
  LL_TIM_OC_EnablePreload(TIM2, LL_TIM_CHANNEL_CH2);
  LL_TIM_OC_Init(TIM2, LL_TIM_CHANNEL_CH2, &TIM_OC_InitStruct);
  LL_TIM_OC_DisableFast(TIM2, LL_TIM_CHANNEL_CH2);
  LL_TIM_OC_EnablePreload(TIM2, LL_TIM_CHANNEL_CH3);
  LL_TIM_OC_Init(TIM2, LL_TIM_CHANNEL_CH3, &TIM_OC_InitStruct);
  LL_TIM_OC_DisableFast(TIM2, LL_TIM_CHANNEL_CH3);
  LL_TIM_OC_EnablePreload(TIM2, LL_TIM_CHANNEL_CH4);
  LL_TIM_OC_Init(TIM2, LL_TIM_CHANNEL_CH4, &TIM_OC_InitStruct);
  LL_TIM_OC_DisableFast(TIM2, LL_TIM_CHANNEL_CH4);
  LL_TIM_SetTriggerOutput(TIM2, LL_TIM_TRGO_RESET);
  LL_TIM_DisableMasterSlaveMode(TIM2);
  LL_AHB4_GRP1_EnableClock(LL_AHB4_GRP1_PERIPH_GPIOA);
  /**TIM2 GPIO Configuration
  PA0   ------> TIM2_CH1
  PA1   ------> TIM2_CH2
  PA2   ------> TIM2_CH3
  PA3   ------> TIM2_CH4
  */
  GPIO_InitStruct.Pin = LL_GPIO_PIN_0|LL_GPIO_PIN_1|LL_GPIO_PIN_2|LL_GPIO_PIN_3;
  GPIO_InitStruct.Mode = LL_GPIO_MODE_ALTERNATE;
  GPIO_InitStruct.Speed = LL_GPIO_SPEED_FREQ_HIGH;
  GPIO_InitStruct.OutputType = LL_GPIO_OUTPUT_PUSHPULL;
  GPIO_InitStruct.Pull = LL_GPIO_PULL_NO;
  GPIO_InitStruct.Alternate = LL_GPIO_AF_1;
  LL_GPIO_Init(GPIOA, &GPIO_InitStruct);

}

static void MX_TIM3_Init(void)
{

  LL_TIM_InitTypeDef TIM_InitStruct = {0};
  LL_TIM_OC_InitTypeDef TIM_OC_InitStruct = {0};

  LL_GPIO_InitTypeDef GPIO_InitStruct = {0};

  /* Peripheral clock enable */
  LL_APB1_GRP1_EnableClock(LL_APB1_GRP1_PERIPH_TIM3);

  TIM_InitStruct.Prescaler = 119;
  TIM_InitStruct.CounterMode = LL_TIM_COUNTERMODE_UP;
  TIM_InitStruct.Autoreload = 65535;
  TIM_InitStruct.ClockDivision = LL_TIM_CLOCKDIVISION_DIV1;
  LL_TIM_Init(TIM3, &TIM_InitStruct);
  LL_TIM_DisableARRPreload(TIM3);
  LL_TIM_SetClockSource(TIM3, LL_TIM_CLOCKSOURCE_INTERNAL);
  LL_TIM_OC_EnablePreload(TIM3, LL_TIM_CHANNEL_CH1);
  TIM_OC_InitStruct.OCMode = LL_TIM_OCMODE_PWM1;
  TIM_OC_InitStruct.OCState = LL_TIM_OCSTATE_DISABLE;
  TIM_OC_InitStruct.OCNState = LL_TIM_OCSTATE_DISABLE;
  TIM_OC_InitStruct.CompareValue = 0;
  TIM_OC_InitStruct.OCPolarity = LL_TIM_OCPOLARITY_HIGH;
  LL_TIM_OC_Init(TIM3, LL_TIM_CHANNEL_CH1, &TIM_OC_InitStruct);
  LL_TIM_OC_DisableFast(TIM3, LL_TIM_CHANNEL_CH1);
  LL_TIM_OC_EnablePreload(TIM3, LL_TIM_CHANNEL_CH2);
  LL_TIM_OC_Init(TIM3, LL_TIM_CHANNEL_CH2, &TIM_OC_InitStruct);
  LL_TIM_OC_DisableFast(TIM3, LL_TIM_CHANNEL_CH2);
  LL_TIM_OC_EnablePreload(TIM3, LL_TIM_CHANNEL_CH3);
  LL_TIM_OC_Init(TIM3, LL_TIM_CHANNEL_CH3, &TIM_OC_InitStruct);
  LL_TIM_OC_DisableFast(TIM3, LL_TIM_CHANNEL_CH3);
  LL_TIM_OC_EnablePreload(TIM3, LL_TIM_CHANNEL_CH4);
  LL_TIM_OC_Init(TIM3, LL_TIM_CHANNEL_CH4, &TIM_OC_InitStruct);
  LL_TIM_OC_DisableFast(TIM3, LL_TIM_CHANNEL_CH4);
  LL_TIM_SetTriggerOutput(TIM3, LL_TIM_TRGO_RESET);
  LL_TIM_DisableMasterSlaveMode(TIM3);
  LL_AHB4_GRP1_EnableClock(LL_AHB4_GRP1_PERIPH_GPIOB);
  LL_AHB4_GRP1_EnableClock(LL_AHB4_GRP1_PERIPH_GPIOC);
  /**TIM3 GPIO Configuration
  PB1   ------> TIM3_CH4
  PC8   ------> TIM3_CH3
  PB4(NJTRST)   ------> TIM3_CH1
  PB5   ------> TIM3_CH2
  */
  GPIO_InitStruct.Pin = LL_GPIO_PIN_1|LL_GPIO_PIN_4|LL_GPIO_PIN_5;
  GPIO_InitStruct.Mode = LL_GPIO_MODE_ALTERNATE;
  GPIO_InitStruct.Speed = LL_GPIO_SPEED_FREQ_HIGH;
  GPIO_InitStruct.OutputType = LL_GPIO_OUTPUT_PUSHPULL;
  GPIO_InitStruct.Pull = LL_GPIO_PULL_NO;
  GPIO_InitStruct.Alternate = LL_GPIO_AF_2;
  LL_GPIO_Init(GPIOB, &GPIO_InitStruct);

  GPIO_InitStruct.Pin = LL_GPIO_PIN_8;
  GPIO_InitStruct.Mode = LL_GPIO_MODE_ALTERNATE;
  GPIO_InitStruct.Speed = LL_GPIO_SPEED_FREQ_HIGH;
  GPIO_InitStruct.OutputType = LL_GPIO_OUTPUT_PUSHPULL;
  GPIO_InitStruct.Pull = LL_GPIO_PULL_NO;
  GPIO_InitStruct.Alternate = LL_GPIO_AF_2;
  LL_GPIO_Init(GPIOC, &GPIO_InitStruct);

}

static void MX_TIM4_Init(void)
{

  LL_TIM_InitTypeDef TIM_InitStruct = {0};
  LL_TIM_OC_InitTypeDef TIM_OC_InitStruct = {0};

  LL_GPIO_InitTypeDef GPIO_InitStruct = {0};

  /* Peripheral clock enable */
  LL_APB1_GRP1_EnableClock(LL_APB1_GRP1_PERIPH_TIM4);

  TIM_InitStruct.Prescaler = 119;
  TIM_InitStruct.CounterMode = LL_TIM_COUNTERMODE_UP;
  TIM_InitStruct.Autoreload = 999;
  TIM_InitStruct.ClockDivision = LL_TIM_CLOCKDIVISION_DIV1;
  LL_TIM_Init(TIM4, &TIM_InitStruct);
  LL_TIM_EnableARRPreload(TIM4);
  LL_TIM_SetClockSource(TIM4, LL_TIM_CLOCKSOURCE_INTERNAL);
  LL_TIM_OC_EnablePreload(TIM4, LL_TIM_CHANNEL_CH2);
  TIM_OC_InitStruct.OCMode = LL_TIM_OCMODE_PWM1;
  TIM_OC_InitStruct.OCState = LL_TIM_OCSTATE_DISABLE;
  TIM_OC_InitStruct.OCNState = LL_TIM_OCSTATE_DISABLE;
  TIM_OC_InitStruct.CompareValue = 0;
  TIM_OC_InitStruct.OCPolarity = LL_TIM_OCPOLARITY_HIGH;
  LL_TIM_OC_Init(TIM4, LL_TIM_CHANNEL_CH2, &TIM_OC_InitStruct);
  LL_TIM_OC_DisableFast(TIM4, LL_TIM_CHANNEL_CH2);
  LL_TIM_OC_EnablePreload(TIM4, LL_TIM_CHANNEL_CH3);
  LL_TIM_OC_Init(TIM4, LL_TIM_CHANNEL_CH3, &TIM_OC_InitStruct);
  LL_TIM_OC_DisableFast(TIM4, LL_TIM_CHANNEL_CH3);
  LL_TIM_OC_EnablePreload(TIM4, LL_TIM_CHANNEL_CH4);
  LL_TIM_OC_Init(TIM4, LL_TIM_CHANNEL_CH4, &TIM_OC_InitStruct);
  LL_TIM_OC_DisableFast(TIM4, LL_TIM_CHANNEL_CH4);
  LL_TIM_SetTriggerOutput(TIM4, LL_TIM_TRGO_RESET);
  LL_TIM_DisableMasterSlaveMode(TIM4);
  LL_AHB4_GRP1_EnableClock(LL_AHB4_GRP1_PERIPH_GPIOD);
  /**TIM4 GPIO Configuration
  PD13   ------> TIM4_CH2
  PD14   ------> TIM4_CH3
  PD15   ------> TIM4_CH4
  */
  GPIO_InitStruct.Pin = RGB_B_Pin|RGB_G_Pin|RGB_R_Pin;
  GPIO_InitStruct.Mode = LL_GPIO_MODE_ALTERNATE;
  GPIO_InitStruct.Speed = LL_GPIO_SPEED_FREQ_LOW;
  GPIO_InitStruct.OutputType = LL_GPIO_OUTPUT_PUSHPULL;
  GPIO_InitStruct.Pull = LL_GPIO_PULL_NO;
  GPIO_InitStruct.Alternate = LL_GPIO_AF_2;
  LL_GPIO_Init(GPIOD, &GPIO_InitStruct);

}

static void MX_TIM8_Init(void)
{

  LL_TIM_InitTypeDef TIM_InitStruct = {0};
  LL_TIM_OC_InitTypeDef TIM_OC_InitStruct = {0};
  LL_TIM_BDTR_InitTypeDef TIM_BDTRInitStruct = {0};

  LL_GPIO_InitTypeDef GPIO_InitStruct = {0};

  /* Peripheral clock enable */
  LL_APB2_GRP1_EnableClock(LL_APB2_GRP1_PERIPH_TIM8);

  /* TIM8 DMA Init */

  /* TIM8_UP Init */
  LL_DMA_SetPeriphRequest(DMA1, LL_DMA_STREAM_1, LL_DMAMUX1_REQ_TIM8_UP);

  LL_DMA_SetDataTransferDirection(DMA1, LL_DMA_STREAM_1, LL_DMA_DIRECTION_PERIPH_TO_MEMORY);

  LL_DMA_SetStreamPriorityLevel(DMA1, LL_DMA_STREAM_1, LL_DMA_PRIORITY_HIGH);

  LL_DMA_SetMode(DMA1, LL_DMA_STREAM_1, LL_DMA_MODE_NORMAL);

  LL_DMA_SetPeriphIncMode(DMA1, LL_DMA_STREAM_1, LL_DMA_PERIPH_NOINCREMENT);

  LL_DMA_SetMemoryIncMode(DMA1, LL_DMA_STREAM_1, LL_DMA_MEMORY_INCREMENT);

  LL_DMA_SetPeriphSize(DMA1, LL_DMA_STREAM_1, LL_DMA_PDATAALIGN_HALFWORD);

  LL_DMA_SetMemorySize(DMA1, LL_DMA_STREAM_1, LL_DMA_MDATAALIGN_HALFWORD);

  LL_DMA_DisableFifoMode(DMA1, LL_DMA_STREAM_1);

  TIM_InitStruct.Prescaler = 0;
  TIM_InitStruct.CounterMode = LL_TIM_COUNTERMODE_UP;
  TIM_InitStruct.Autoreload = 65535;
  TIM_InitStruct.ClockDivision = LL_TIM_CLOCKDIVISION_DIV1;
  TIM_InitStruct.RepetitionCounter = 0;
  LL_TIM_Init(TIM8, &TIM_InitStruct);
  LL_TIM_DisableARRPreload(TIM8);
  TIM_OC_InitStruct.OCMode = LL_TIM_OCMODE_FROZEN;
  TIM_OC_InitStruct.OCState = LL_TIM_OCSTATE_DISABLE;
  TIM_OC_InitStruct.OCNState = LL_TIM_OCSTATE_DISABLE;
  TIM_OC_InitStruct.CompareValue = 0;
  TIM_OC_InitStruct.OCPolarity = LL_TIM_OCPOLARITY_HIGH;
  TIM_OC_InitStruct.OCNPolarity = LL_TIM_OCPOLARITY_HIGH;
  TIM_OC_InitStruct.OCIdleState = LL_TIM_OCIDLESTATE_LOW;
  TIM_OC_InitStruct.OCNIdleState = LL_TIM_OCIDLESTATE_LOW;
  LL_TIM_OC_Init(TIM8, LL_TIM_CHANNEL_CH1, &TIM_OC_InitStruct);
  LL_TIM_OC_DisableFast(TIM8, LL_TIM_CHANNEL_CH1);
  LL_TIM_OC_Init(TIM8, LL_TIM_CHANNEL_CH2, &TIM_OC_InitStruct);
  LL_TIM_OC_DisableFast(TIM8, LL_TIM_CHANNEL_CH2);
  LL_TIM_SetTriggerOutput(TIM8, LL_TIM_TRGO_RESET);
  LL_TIM_SetTriggerOutput2(TIM8, LL_TIM_TRGO2_RESET);
  LL_TIM_DisableMasterSlaveMode(TIM8);
  TIM_BDTRInitStruct.OSSRState = LL_TIM_OSSR_DISABLE;
  TIM_BDTRInitStruct.OSSIState = LL_TIM_OSSI_DISABLE;
  TIM_BDTRInitStruct.LockLevel = LL_TIM_LOCKLEVEL_OFF;
  TIM_BDTRInitStruct.DeadTime = 0;
  TIM_BDTRInitStruct.BreakState = LL_TIM_BREAK_DISABLE;
  TIM_BDTRInitStruct.BreakPolarity = LL_TIM_BREAK_POLARITY_HIGH;
  TIM_BDTRInitStruct.BreakFilter = LL_TIM_BREAK_FILTER_FDIV1;
  TIM_BDTRInitStruct.Break2State = LL_TIM_BREAK2_DISABLE;
  TIM_BDTRInitStruct.Break2Polarity = LL_TIM_BREAK2_POLARITY_HIGH;
  TIM_BDTRInitStruct.Break2Filter = LL_TIM_BREAK2_FILTER_FDIV1;
  TIM_BDTRInitStruct.AutomaticOutput = LL_TIM_AUTOMATICOUTPUT_DISABLE;
  LL_TIM_BDTR_Init(TIM8, &TIM_BDTRInitStruct);
  LL_AHB4_GRP1_EnableClock(LL_AHB4_GRP1_PERIPH_GPIOC);
  /**TIM8 GPIO Configuration
  PC6   ------> TIM8_CH1
  PC7   ------> TIM8_CH2
  */
  GPIO_InitStruct.Pin = LL_GPIO_PIN_6|LL_GPIO_PIN_7;
  GPIO_InitStruct.Mode = LL_GPIO_MODE_ALTERNATE;
  GPIO_InitStruct.Speed = LL_GPIO_SPEED_FREQ_LOW;
  GPIO_InitStruct.OutputType = LL_GPIO_OUTPUT_PUSHPULL;
  GPIO_InitStruct.Pull = LL_GPIO_PULL_NO;
  GPIO_InitStruct.Alternate = LL_GPIO_AF_3;
  LL_GPIO_Init(GPIOC, &GPIO_InitStruct);

}

static void MX_TIM23_Init(void)
{

  LL_TIM_InitTypeDef TIM_InitStruct = {0};

  /* Peripheral clock enable */
  LL_APB1_GRP2_EnableClock(LL_APB1_GRP2_PERIPH_TIM23);

  TIM_InitStruct.Prescaler = 59999;
  TIM_InitStruct.CounterMode = LL_TIM_COUNTERMODE_UP;
  TIM_InitStruct.Autoreload = 4294967295;
  TIM_InitStruct.ClockDivision = LL_TIM_CLOCKDIVISION_DIV1;
  LL_TIM_Init(TIM23, &TIM_InitStruct);
  LL_TIM_DisableARRPreload(TIM23);
  LL_TIM_SetClockSource(TIM23, LL_TIM_CLOCKSOURCE_INTERNAL);
  LL_TIM_SetTriggerOutput(TIM23, LL_TIM_TRGO_RESET);
  LL_TIM_DisableMasterSlaveMode(TIM23);

}

static void MX_TIM24_Init(void)
{

  LL_TIM_InitTypeDef TIM_InitStruct = {0};

  /* Peripheral clock enable */
  LL_APB1_GRP2_EnableClock(LL_APB1_GRP2_PERIPH_TIM24);

  TIM_InitStruct.Prescaler = 119;
  TIM_InitStruct.CounterMode = LL_TIM_COUNTERMODE_UP;
  TIM_InitStruct.Autoreload = 4294967295;
  TIM_InitStruct.ClockDivision = LL_TIM_CLOCKDIVISION_DIV1;
  LL_TIM_Init(TIM24, &TIM_InitStruct);
  LL_TIM_DisableARRPreload(TIM24);
  LL_TIM_SetClockSource(TIM24, LL_TIM_CLOCKSOURCE_INTERNAL);
  LL_TIM_SetTriggerOutput(TIM24, LL_TIM_TRGO_RESET);
  LL_TIM_DisableMasterSlaveMode(TIM24);

}

static void MX_UART4_Init(void)
{

  huart4.Instance = UART4;
  huart4.Init.BaudRate = 416666;
  huart4.Init.WordLength = UART_WORDLENGTH_8B;
  huart4.Init.StopBits = UART_STOPBITS_1;
  huart4.Init.Parity = UART_PARITY_NONE;
  huart4.Init.Mode = UART_MODE_TX_RX;
  huart4.Init.HwFlowCtl = UART_HWCONTROL_NONE;
  huart4.Init.OverSampling = UART_OVERSAMPLING_16;
  huart4.Init.OneBitSampling = UART_ONE_BIT_SAMPLE_DISABLE;
  huart4.Init.ClockPrescaler = UART_PRESCALER_DIV1;
  huart4.AdvancedInit.AdvFeatureInit = UART_ADVFEATURE_NO_INIT;
  if (HAL_UART_Init(&huart4) != HAL_OK)
  {
    Error_Handler();
  }
  if (HAL_UARTEx_SetTxFifoThreshold(&huart4, UART_TXFIFO_THRESHOLD_1_8) != HAL_OK)
  {
    Error_Handler();
  }
  if (HAL_UARTEx_SetRxFifoThreshold(&huart4, UART_RXFIFO_THRESHOLD_1_8) != HAL_OK)
  {
    Error_Handler();
  }
  if (HAL_UARTEx_DisableFifoMode(&huart4) != HAL_OK)
  {
    Error_Handler();
  }

}

static void MX_UART5_Init(void)
{

  huart5.Instance = UART5;
  huart5.Init.BaudRate = 576000;
  huart5.Init.WordLength = UART_WORDLENGTH_8B;
  huart5.Init.StopBits = UART_STOPBITS_1;
  huart5.Init.Parity = UART_PARITY_NONE;
  huart5.Init.Mode = UART_MODE_TX_RX;
  huart5.Init.HwFlowCtl = UART_HWCONTROL_NONE;
  huart5.Init.OverSampling = UART_OVERSAMPLING_16;
  huart5.Init.OneBitSampling = UART_ONE_BIT_SAMPLE_DISABLE;
  huart5.Init.ClockPrescaler = UART_PRESCALER_DIV1;
  huart5.AdvancedInit.AdvFeatureInit = UART_ADVFEATURE_NO_INIT;
  if (HAL_UART_Init(&huart5) != HAL_OK)
  {
    Error_Handler();
  }
  if (HAL_UARTEx_SetTxFifoThreshold(&huart5, UART_TXFIFO_THRESHOLD_1_8) != HAL_OK)
  {
    Error_Handler();
  }
  if (HAL_UARTEx_SetRxFifoThreshold(&huart5, UART_RXFIFO_THRESHOLD_1_8) != HAL_OK)
  {
    Error_Handler();
  }
  if (HAL_UARTEx_DisableFifoMode(&huart5) != HAL_OK)
  {
    Error_Handler();
  }

}

static void MX_UART7_Init(void)
{

  huart7.Instance = UART7;
  huart7.Init.BaudRate = 115200;
  huart7.Init.WordLength = UART_WORDLENGTH_8B;
  huart7.Init.StopBits = UART_STOPBITS_1;
  huart7.Init.Parity = UART_PARITY_NONE;
  huart7.Init.Mode = UART_MODE_TX_RX;
  huart7.Init.HwFlowCtl = UART_HWCONTROL_NONE;
  huart7.Init.OverSampling = UART_OVERSAMPLING_16;
  huart7.Init.OneBitSampling = UART_ONE_BIT_SAMPLE_DISABLE;
  huart7.Init.ClockPrescaler = UART_PRESCALER_DIV1;
  huart7.AdvancedInit.AdvFeatureInit = UART_ADVFEATURE_NO_INIT;
  if (HAL_UART_Init(&huart7) != HAL_OK)
  {
    Error_Handler();
  }
  if (HAL_UARTEx_SetTxFifoThreshold(&huart7, UART_TXFIFO_THRESHOLD_1_8) != HAL_OK)
  {
    Error_Handler();
  }
  if (HAL_UARTEx_SetRxFifoThreshold(&huart7, UART_RXFIFO_THRESHOLD_1_8) != HAL_OK)
  {
    Error_Handler();
  }
  if (HAL_UARTEx_DisableFifoMode(&huart7) != HAL_OK)
  {
    Error_Handler();
  }

}

static void MX_UART8_Init(void)
{

  huart8.Instance = UART8;
  huart8.Init.BaudRate = 115200;
  huart8.Init.WordLength = UART_WORDLENGTH_8B;
  huart8.Init.StopBits = UART_STOPBITS_1;
  huart8.Init.Parity = UART_PARITY_NONE;
  huart8.Init.Mode = UART_MODE_TX_RX;
  huart8.Init.HwFlowCtl = UART_HWCONTROL_NONE;
  huart8.Init.OverSampling = UART_OVERSAMPLING_16;
  huart8.Init.OneBitSampling = UART_ONE_BIT_SAMPLE_DISABLE;
  huart8.Init.ClockPrescaler = UART_PRESCALER_DIV1;
  huart8.AdvancedInit.AdvFeatureInit = UART_ADVFEATURE_NO_INIT;
  if (HAL_UART_Init(&huart8) != HAL_OK)
  {
    Error_Handler();
  }
  if (HAL_UARTEx_SetTxFifoThreshold(&huart8, UART_TXFIFO_THRESHOLD_1_8) != HAL_OK)
  {
    Error_Handler();
  }
  if (HAL_UARTEx_SetRxFifoThreshold(&huart8, UART_RXFIFO_THRESHOLD_1_8) != HAL_OK)
  {
    Error_Handler();
  }
  if (HAL_UARTEx_DisableFifoMode(&huart8) != HAL_OK)
  {
    Error_Handler();
  }

}

static void MX_USART2_UART_Init(void)
{

  huart2.Instance = USART2;
  huart2.Init.BaudRate = 416666;
  huart2.Init.WordLength = UART_WORDLENGTH_8B;
  huart2.Init.StopBits = UART_STOPBITS_1;
  huart2.Init.Parity = UART_PARITY_NONE;
  huart2.Init.Mode = UART_MODE_TX_RX;
  huart2.Init.HwFlowCtl = UART_HWCONTROL_NONE;
  huart2.Init.OverSampling = UART_OVERSAMPLING_16;
  huart2.Init.OneBitSampling = UART_ONE_BIT_SAMPLE_DISABLE;
  huart2.Init.ClockPrescaler = UART_PRESCALER_DIV1;
  huart2.AdvancedInit.AdvFeatureInit = UART_ADVFEATURE_NO_INIT;
  if (HAL_UART_Init(&huart2) != HAL_OK)
  {
    Error_Handler();
  }
  if (HAL_UARTEx_SetTxFifoThreshold(&huart2, UART_TXFIFO_THRESHOLD_1_8) != HAL_OK)
  {
    Error_Handler();
  }
  if (HAL_UARTEx_SetRxFifoThreshold(&huart2, UART_RXFIFO_THRESHOLD_1_8) != HAL_OK)
  {
    Error_Handler();
  }
  if (HAL_UARTEx_DisableFifoMode(&huart2) != HAL_OK)
  {
    Error_Handler();
  }

}

static void MX_USART3_UART_Init(void)
{

  huart3.Instance = USART3;
  huart3.Init.BaudRate = 230400;
  huart3.Init.WordLength = UART_WORDLENGTH_8B;
  huart3.Init.StopBits = UART_STOPBITS_1;
  huart3.Init.Parity = UART_PARITY_NONE;
  huart3.Init.Mode = UART_MODE_TX_RX;
  huart3.Init.HwFlowCtl = UART_HWCONTROL_NONE;
  huart3.Init.OverSampling = UART_OVERSAMPLING_16;
  huart3.Init.OneBitSampling = UART_ONE_BIT_SAMPLE_DISABLE;
  huart3.Init.ClockPrescaler = UART_PRESCALER_DIV1;
  huart3.AdvancedInit.AdvFeatureInit = UART_ADVFEATURE_NO_INIT;
  if (HAL_UART_Init(&huart3) != HAL_OK)
  {
    Error_Handler();
  }
  if (HAL_UARTEx_SetTxFifoThreshold(&huart3, UART_TXFIFO_THRESHOLD_1_8) != HAL_OK)
  {
    Error_Handler();
  }
  if (HAL_UARTEx_SetRxFifoThreshold(&huart3, UART_RXFIFO_THRESHOLD_1_8) != HAL_OK)
  {
    Error_Handler();
  }
  if (HAL_UARTEx_DisableFifoMode(&huart3) != HAL_OK)
  {
    Error_Handler();
  }

}

static void MX_DMA_Init(void)
{

  /* DMA controller clock enable */
  __HAL_RCC_DMA1_CLK_ENABLE();
  __HAL_RCC_DMA2_CLK_ENABLE();

  /* DMA interrupt init */
  /* DMA1_Stream0_IRQn interrupt configuration */
  NVIC_SetPriority(DMA1_Stream0_IRQn, NVIC_EncodePriority(NVIC_GetPriorityGrouping(),0, 0));
  NVIC_EnableIRQ(DMA1_Stream0_IRQn);
  /* DMA1_Stream1_IRQn interrupt configuration */
  NVIC_SetPriority(DMA1_Stream1_IRQn, NVIC_EncodePriority(NVIC_GetPriorityGrouping(),0, 0));
  NVIC_EnableIRQ(DMA1_Stream1_IRQn);
  /* DMA1_Stream2_IRQn interrupt configuration */
  HAL_NVIC_SetPriority(DMA1_Stream2_IRQn, 0, 0);
  HAL_NVIC_EnableIRQ(DMA1_Stream2_IRQn);
  /* DMA1_Stream3_IRQn interrupt configuration */
  HAL_NVIC_SetPriority(DMA1_Stream3_IRQn, 0, 0);
  HAL_NVIC_EnableIRQ(DMA1_Stream3_IRQn);
  /* DMA1_Stream4_IRQn interrupt configuration */
  HAL_NVIC_SetPriority(DMA1_Stream4_IRQn, 0, 0);
  HAL_NVIC_EnableIRQ(DMA1_Stream4_IRQn);
  /* DMA1_Stream5_IRQn interrupt configuration */
  HAL_NVIC_SetPriority(DMA1_Stream5_IRQn, 0, 0);
  HAL_NVIC_EnableIRQ(DMA1_Stream5_IRQn);
  /* DMA1_Stream6_IRQn interrupt configuration */
  HAL_NVIC_SetPriority(DMA1_Stream6_IRQn, 0, 0);
  HAL_NVIC_EnableIRQ(DMA1_Stream6_IRQn);
  /* DMA1_Stream7_IRQn interrupt configuration */
  HAL_NVIC_SetPriority(DMA1_Stream7_IRQn, 0, 0);
  HAL_NVIC_EnableIRQ(DMA1_Stream7_IRQn);
  /* DMA2_Stream0_IRQn interrupt configuration */
  HAL_NVIC_SetPriority(DMA2_Stream0_IRQn, 0, 0);
  HAL_NVIC_EnableIRQ(DMA2_Stream0_IRQn);
  /* DMA2_Stream1_IRQn interrupt configuration */
  HAL_NVIC_SetPriority(DMA2_Stream1_IRQn, 0, 0);
  HAL_NVIC_EnableIRQ(DMA2_Stream1_IRQn);

}

static void MX_GPIO_Init(void)
{
  LL_EXTI_InitTypeDef EXTI_InitStruct = {0};
  LL_GPIO_InitTypeDef GPIO_InitStruct = {0};

  /* GPIO Ports Clock Enable */
  LL_AHB4_GRP1_EnableClock(LL_AHB4_GRP1_PERIPH_GPIOE);
  LL_AHB4_GRP1_EnableClock(LL_AHB4_GRP1_PERIPH_GPIOC);
  LL_AHB4_GRP1_EnableClock(LL_AHB4_GRP1_PERIPH_GPIOH);
  LL_AHB4_GRP1_EnableClock(LL_AHB4_GRP1_PERIPH_GPIOA);
  LL_AHB4_GRP1_EnableClock(LL_AHB4_GRP1_PERIPH_GPIOB);
  LL_AHB4_GRP1_EnableClock(LL_AHB4_GRP1_PERIPH_GPIOD);

  /**/
  LL_GPIO_ResetOutputPin(BARO_CS_GPIO_Port, BARO_CS_Pin);

  /**/
  LL_GPIO_ResetOutputPin(GPIOC, MAGNETO_CS_Pin|IMU_CS_Pin);

  /**/
  LL_SYSCFG_SetEXTISource(LL_SYSCFG_EXTI_PORTE, LL_SYSCFG_EXTI_LINE3);

  /**/
  LL_SYSCFG_SetEXTISource(LL_SYSCFG_EXTI_PORTC, LL_SYSCFG_EXTI_LINE0);

  /**/
  LL_SYSCFG_SetEXTISource(LL_SYSCFG_EXTI_PORTA, LL_SYSCFG_EXTI_LINE4);

  /**/
  LL_SYSCFG_SetEXTISource(LL_SYSCFG_EXTI_PORTB, LL_SYSCFG_EXTI_LINE2);

  /**/
  LL_SYSCFG_SetEXTISource(LL_SYSCFG_EXTI_PORTA, LL_SYSCFG_EXTI_LINE10);

  /**/
  EXTI_InitStruct.Line_0_31 = LL_EXTI_LINE_3;
  EXTI_InitStruct.Line_32_63 = LL_EXTI_LINE_NONE;
  EXTI_InitStruct.Line_64_95 = LL_EXTI_LINE_NONE;
  EXTI_InitStruct.LineCommand = ENABLE;
  EXTI_InitStruct.Mode = LL_EXTI_MODE_IT;
  EXTI_InitStruct.Trigger = LL_EXTI_TRIGGER_RISING;
  LL_EXTI_Init(&EXTI_InitStruct);

  /**/
  EXTI_InitStruct.Line_0_31 = LL_EXTI_LINE_0;
  EXTI_InitStruct.Line_32_63 = LL_EXTI_LINE_NONE;
  EXTI_InitStruct.Line_64_95 = LL_EXTI_LINE_NONE;
  EXTI_InitStruct.LineCommand = ENABLE;
  EXTI_InitStruct.Mode = LL_EXTI_MODE_IT;
  EXTI_InitStruct.Trigger = LL_EXTI_TRIGGER_RISING;
  LL_EXTI_Init(&EXTI_InitStruct);

  /**/
  EXTI_InitStruct.Line_0_31 = LL_EXTI_LINE_4;
  EXTI_InitStruct.Line_32_63 = LL_EXTI_LINE_NONE;
  EXTI_InitStruct.Line_64_95 = LL_EXTI_LINE_NONE;
  EXTI_InitStruct.LineCommand = ENABLE;
  EXTI_InitStruct.Mode = LL_EXTI_MODE_IT;
  EXTI_InitStruct.Trigger = LL_EXTI_TRIGGER_RISING;
  LL_EXTI_Init(&EXTI_InitStruct);

  /**/
  EXTI_InitStruct.Line_0_31 = LL_EXTI_LINE_2;
  EXTI_InitStruct.Line_32_63 = LL_EXTI_LINE_NONE;
  EXTI_InitStruct.Line_64_95 = LL_EXTI_LINE_NONE;
  EXTI_InitStruct.LineCommand = ENABLE;
  EXTI_InitStruct.Mode = LL_EXTI_MODE_IT;
  EXTI_InitStruct.Trigger = LL_EXTI_TRIGGER_RISING;
  LL_EXTI_Init(&EXTI_InitStruct);

  /**/
  EXTI_InitStruct.Line_0_31 = LL_EXTI_LINE_10;
  EXTI_InitStruct.Line_32_63 = LL_EXTI_LINE_NONE;
  EXTI_InitStruct.Line_64_95 = LL_EXTI_LINE_NONE;
  EXTI_InitStruct.LineCommand = ENABLE;
  EXTI_InitStruct.Mode = LL_EXTI_MODE_IT;
  EXTI_InitStruct.Trigger = LL_EXTI_TRIGGER_RISING;
  LL_EXTI_Init(&EXTI_InitStruct);

  /**/
  LL_GPIO_SetPinPull(BARO_EXTI_GPIO_Port, BARO_EXTI_Pin, LL_GPIO_PULL_NO);

  /**/
  LL_GPIO_SetPinPull(MAGNETO_EXTI_GPIO_Port, MAGNETO_EXTI_Pin, LL_GPIO_PULL_NO);

  /**/
  LL_GPIO_SetPinPull(IMU_EXTI_2_GPIO_Port, IMU_EXTI_2_Pin, LL_GPIO_PULL_NO);

  /**/
  LL_GPIO_SetPinPull(IMU_EXTI_1_GPIO_Port, IMU_EXTI_1_Pin, LL_GPIO_PULL_NO);

  /**/
  LL_GPIO_SetPinPull(POWER_GOOD_EXTI_GPIO_Port, POWER_GOOD_EXTI_Pin, LL_GPIO_PULL_NO);

  /**/
  LL_GPIO_SetPinMode(BARO_EXTI_GPIO_Port, BARO_EXTI_Pin, LL_GPIO_MODE_INPUT);

  /**/
  LL_GPIO_SetPinMode(MAGNETO_EXTI_GPIO_Port, MAGNETO_EXTI_Pin, LL_GPIO_MODE_INPUT);

  /**/
  LL_GPIO_SetPinMode(IMU_EXTI_2_GPIO_Port, IMU_EXTI_2_Pin, LL_GPIO_MODE_INPUT);

  /**/
  LL_GPIO_SetPinMode(IMU_EXTI_1_GPIO_Port, IMU_EXTI_1_Pin, LL_GPIO_MODE_INPUT);

  /**/
  LL_GPIO_SetPinMode(POWER_GOOD_EXTI_GPIO_Port, POWER_GOOD_EXTI_Pin, LL_GPIO_MODE_INPUT);

  /**/
  GPIO_InitStruct.Pin = BARO_CS_Pin;
  GPIO_InitStruct.Mode = LL_GPIO_MODE_OUTPUT;
  GPIO_InitStruct.Speed = LL_GPIO_SPEED_FREQ_LOW;
  GPIO_InitStruct.OutputType = LL_GPIO_OUTPUT_PUSHPULL;
  GPIO_InitStruct.Pull = LL_GPIO_PULL_NO;
  LL_GPIO_Init(BARO_CS_GPIO_Port, &GPIO_InitStruct);

  /**/
  GPIO_InitStruct.Pin = MAGNETO_CS_Pin|IMU_CS_Pin;
  GPIO_InitStruct.Mode = LL_GPIO_MODE_OUTPUT;
  GPIO_InitStruct.Speed = LL_GPIO_SPEED_FREQ_LOW;
  GPIO_InitStruct.OutputType = LL_GPIO_OUTPUT_PUSHPULL;
  GPIO_InitStruct.Pull = LL_GPIO_PULL_NO;
  LL_GPIO_Init(GPIOC, &GPIO_InitStruct);

  /**/
  GPIO_InitStruct.Pin = LL_GPIO_PIN_0;
  GPIO_InitStruct.Mode = LL_GPIO_MODE_ANALOG;
  GPIO_InitStruct.Pull = LL_GPIO_PULL_NO;
  LL_GPIO_Init(GPIOB, &GPIO_InitStruct);

  /**/
  GPIO_InitStruct.Pin = SD_CARD_DETECT_Pin;
  GPIO_InitStruct.Mode = LL_GPIO_MODE_INPUT;
  GPIO_InitStruct.Pull = LL_GPIO_PULL_NO;
  LL_GPIO_Init(SD_CARD_DETECT_GPIO_Port, &GPIO_InitStruct);

  /* EXTI interrupt init*/
  NVIC_SetPriority(EXTI0_IRQn, NVIC_EncodePriority(NVIC_GetPriorityGrouping(),13, 0));
  NVIC_EnableIRQ(EXTI0_IRQn);
  NVIC_SetPriority(EXTI2_IRQn, NVIC_EncodePriority(NVIC_GetPriorityGrouping(),5, 0));
  NVIC_EnableIRQ(EXTI2_IRQn);
  NVIC_SetPriority(EXTI3_IRQn, NVIC_EncodePriority(NVIC_GetPriorityGrouping(),14, 0));
  NVIC_EnableIRQ(EXTI3_IRQn);
  NVIC_SetPriority(EXTI4_IRQn, NVIC_EncodePriority(NVIC_GetPriorityGrouping(),6, 0));
  NVIC_EnableIRQ(EXTI4_IRQn);

}

 /* MPU Configuration */

void MPU_Config(void)
{

  /* Disables the MPU */
  LL_MPU_Disable();

  /** Initializes and configures the Region and the memory to be protected
  */
  LL_MPU_ConfigRegion(LL_MPU_REGION_NUMBER0, 0x00, 0x24000000, LL_MPU_REGION_SIZE_32KB|LL_MPU_TEX_LEVEL1|LL_MPU_REGION_FULL_ACCESS|LL_MPU_INSTRUCTION_ACCESS_DISABLE|LL_MPU_ACCESS_NOT_SHAREABLE|LL_MPU_ACCESS_NOT_CACHEABLE|LL_MPU_ACCESS_NOT_BUFFERABLE);
  /* Enables the MPU */
  LL_MPU_Enable(LL_MPU_CTRL_HFNMI_PRIVDEF);

}

void Error_Handler(void)
{
  /* USER CODE BEGIN Error_Handler_Debug */
  /* User can add his own implementation to report the HAL error return state */

  MX_TIM4_Init();
  MX_TIM23_Init();
  MX_TIM24_Init();

  STATUS_LED_INIT();
  TIMER_INIT(TIM23, TIM24);
  TIMER_START();

  __disable_irq();
  STATUS_LED_SET_ALL(0);
  uint32_t now = MILLIS32();
  bool led_toggle = false;
  while (1)
  {
    if(((int32_t)(MILLIS32() - now) >= 400 && led_toggle) || ((int32_t)(MILLIS32() - now) >= 50 && !led_toggle)){
      if(led_toggle){
        STATUS_LED_SET_R(999);
      }
      else {
        STATUS_LED_SET_R(0);
      }
      led_toggle = !led_toggle;
      now = MILLIS32();
    }
  }
  /* USER CODE END Error_Handler_Debug */
}
